VERSION ""

NS_ :

BS_:

BU_:

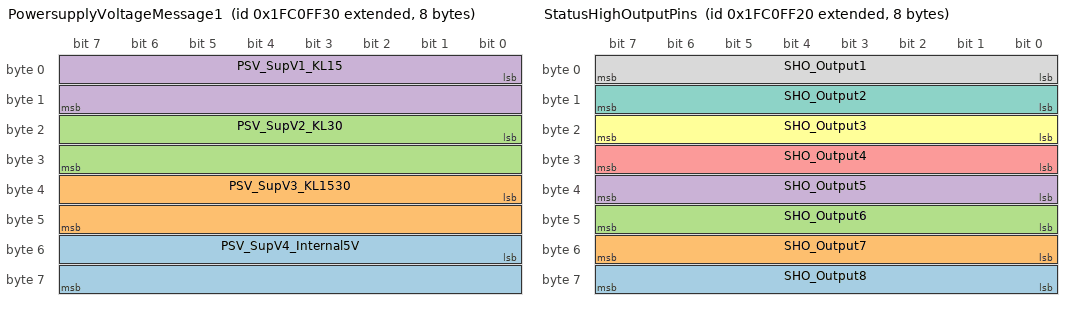
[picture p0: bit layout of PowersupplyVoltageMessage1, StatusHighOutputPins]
BO_ 2680225584 PowersupplyVoltageMessage1: 8 Vector__XXX
 SG_ PSV_SupV4_Internal5V : 48|16@1+ (0.01,0) [0|642.55] "V" Vector__XXX
 SG_ PSV_SupV3_KL1530 : 32|16@1+ (0.01,0) [0|642.55] "V" Vector__XXX
 SG_ PSV_SupV2_KL30 : 16|16@1+ (0.01,0) [0|642.55] "V" Vector__XXX
 SG_ PSV_SupV1_KL15 : 0|16@1+ (0.01,0) [0|642.55] "V" Vector__XXX

BO_ 2680225576 StatusLowOutputPins: 8 Vector__XXX
 SG_ SLO_Output2 : 8|8@1+ (1,0) [0|0] "" Vector__XXX
 SG_ SLO_Output1 : 0|8@1+ (1,0) [0|0] "" Vector__XXX

BO_ 2680225568 StatusHighOutputPins: 8 Vector__XXX
 SG_ SHO_Output8 : 56|8@1+ (1,0) [0|0] "" Vector__XXX
 SG_ SHO_Output7 : 48|8@1+ (1,0) [0|0] "" Vector__XXX
 SG_ SHO_Output6 : 40|8@1+ (1,0) [0|0] "" Vector__XXX
 SG_ SHO_Output5 : 32|8@1+ (1,0) [0|0] "" Vector__XXX
 SG_ SHO_Output4 : 24|8@1+ (1,0) [0|0] "" Vector__XXX
 SG_ SHO_Output3 : 16|8@1+ (1,0) [0|0] "" Vector__XXX
 SG_ SHO_Output2 : 8|8@1+ (1,0) [0|0] "" Vector__XXX
 SG_ SHO_Output1 : 0|8@1+ (1,0) [0|0] "" Vector__XXX

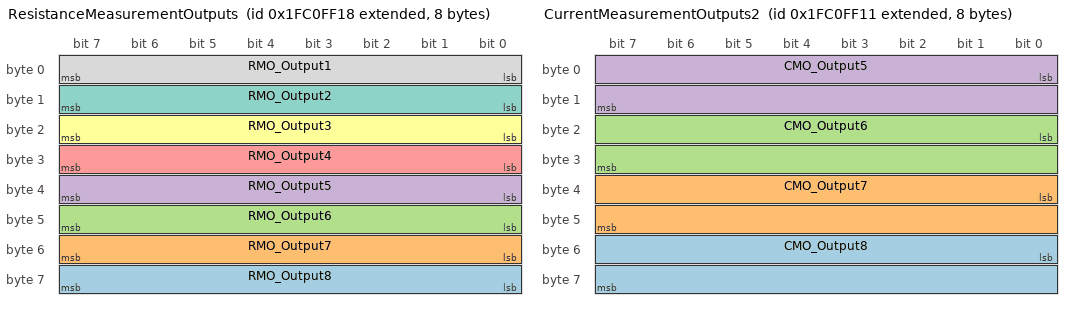
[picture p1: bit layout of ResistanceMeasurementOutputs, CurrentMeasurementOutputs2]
BO_ 2680225560 ResistanceMeasurementOutputs: 8 Vector__XXX
 SG_ RMO_Output8 : 56|8@1+ (0.25,0) [0|60] "Ohm" Vector__XXX
 SG_ RMO_Output7 : 48|8@1+ (0.25,0) [0|60] "Ohm" Vector__XXX
 SG_ RMO_Output6 : 40|8@1+ (0.25,0) [0|60] "Ohm" Vector__XXX
 SG_ RMO_Output5 : 32|8@1+ (0.25,0) [0|60] "Ohm" Vector__XXX
 SG_ RMO_Output4 : 24|8@1+ (0.25,0) [0|60] "Ohm" Vector__XXX
 SG_ RMO_Output3 : 16|8@1+ (0.25,0) [0|60] "Ohm" Vector__XXX
 SG_ RMO_Output2 : 8|8@1+ (0.25,0) [0|60] "Ohm" Vector__XXX
 SG_ RMO_Output1 : 0|8@1+ (0.25,0) [0|60] "Ohm" Vector__XXX

BO_ 2680225553 CurrentMeasurementOutputs2: 8 Vector__XXX
 SG_ CMO_Output8 : 48|16@1+ (0.001,0) [0|64255] "A" Vector__XXX
 SG_ CMO_Output7 : 32|16@1+ (0.001,0) [0|64255] "A" Vector__XXX
 SG_ CMO_Output6 : 16|16@1+ (0.001,0) [0|64255] "A" Vector__XXX
 SG_ CMO_Output5 : 0|16@1+ (0.001,0) [0|64255] "A" Vector__XXX

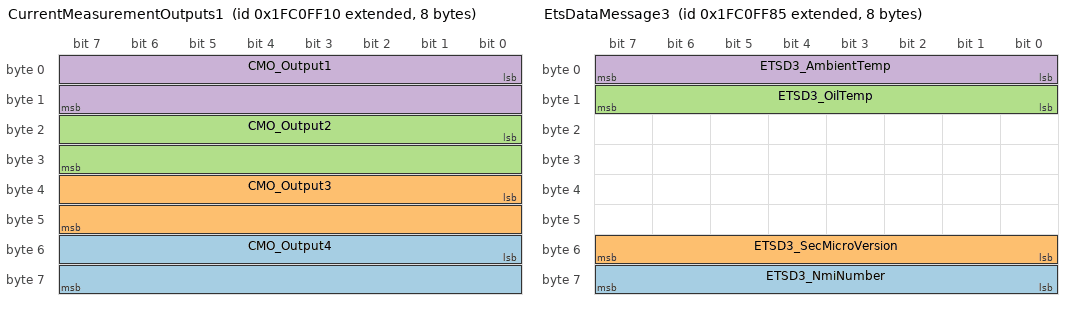
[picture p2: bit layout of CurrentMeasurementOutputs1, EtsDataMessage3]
BO_ 2680225552 CurrentMeasurementOutputs1: 8 Vector__XXX
 SG_ CMO_Output4 : 48|16@1+ (0.001,0) [0|64255] "A" Vector__XXX
 SG_ CMO_Output3 : 32|16@1+ (0.001,0) [0|64255] "A" Vector__XXX
 SG_ CMO_Output2 : 16|16@1+ (0.001,0) [0|64255] "A" Vector__XXX
 SG_ CMO_Output1 : 0|16@1+ (0.001,0) [0|64255] "A" Vector__XXX

BO_ 2680225669 EtsDataMessage3: 8 Vector__XXX
 SG_ ETSD3_NmiNumber : 56|8@1+ (1,0) [0|0] "" Vector__XXX
 SG_ ETSD3_SecMicroVersion : 48|8@1+ (1,0) [0|0] "" Vector__XXX
 SG_ ETSD3_OilTemp : 8|8@1+ (1,-40) [-40|210] "grd" Vector__XXX
 SG_ ETSD3_AmbientTemp : 0|8@1+ (1,-40) [-40|210] "grd" Vector__XXX

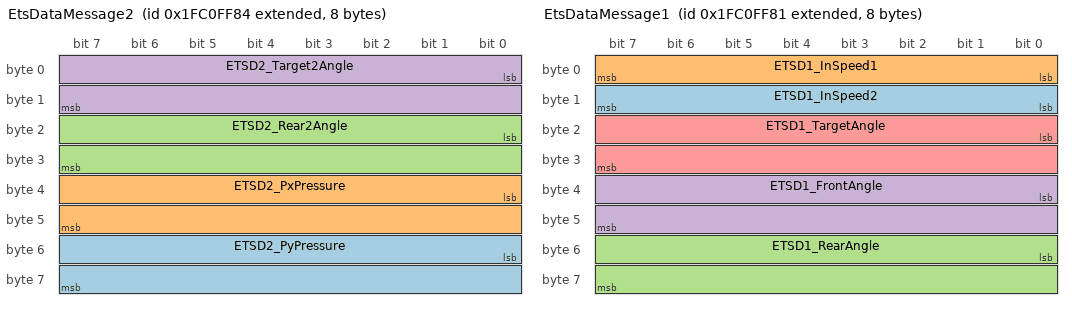
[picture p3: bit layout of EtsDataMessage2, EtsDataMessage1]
BO_ 2680225668 EtsDataMessage2: 8 Vector__XXX
 SG_ ETSD2_PyPressure : 48|16@1+ (0.02,0) [0|0] "Bar" Vector__XXX
 SG_ ETSD2_PxPressure : 32|16@1+ (0.02,0) [0|0] "Bar" Vector__XXX
 SG_ ETSD2_Rear2Angle : 16|16@1+ (0.00390625,-125) [-125|125] "grd" Vector__XXX
 SG_ ETSD2_Target2Angle : 0|16@1+ (0.00390625,-125) [-125|125] "grd" Vector__XXX

BO_ 2680225665 EtsDataMessage1: 8 Vector__XXX
 SG_ ETSD1_InSpeed2 : 8|8@1+ (1,0) [0|250] "km/h" Vector__XXX
 SG_ ETSD1_InSpeed1 : 0|8@1+ (1,0) [0|250] "km/h" Vector__XXX
 SG_ ETSD1_RearAngle : 48|16@1+ (0.00390625,-125) [-125|125] "Grd" Vector__XXX
 SG_ ETSD1_FrontAngle : 32|16@1+ (0.00390625,-125) [-125|125] "Grd" Vector__XXX
 SG_ ETSD1_TargetAngle : 16|16@1+ (0.00390625,-125) [-125|125] "Grd" Vector__XXX

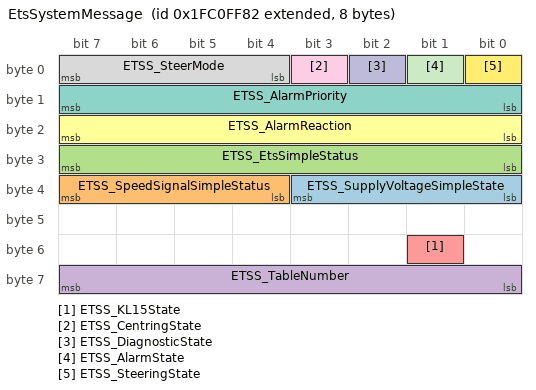
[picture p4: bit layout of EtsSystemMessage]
BO_ 2680225666 EtsSystemMessage: 8 Vector__XXX
 SG_ ETSS_SupplyVoltageSimpleState : 32|4@1+ (1,0) [0|0] "" Vector__XXX
 SG_ ETSS_SpeedSignalSimpleStatus : 36|4@1+ (1,0) [0|0] "" Vector__XXX
 SG_ ETSS_EtsSimpleStatus : 24|8@1+ (1,0) [0|0] "" Vector__XXX
 SG_ ETSS_TableNumber : 56|8@1+ (1,0) [0|255] "" Vector__XXX
 SG_ ETSS_KL15State : 49|1@1+ (1,0) [0|0] "" Vector__XXX
 SG_ ETSS_AlarmReaction : 16|8@1+ (1,0) [0|0] "" Vector__XXX
 SG_ ETSS_AlarmPriority : 8|8@1+ (1,0) [0|0] "" Vector__XXX
 SG_ ETSS_SteerMode : 4|4@1+ (1,0) [0|0] "" Vector__XXX
 SG_ ETSS_CentringState : 3|1@1+ (1,0) [0|0] "" Vector__XXX
 SG_ ETSS_DiagnosticState : 2|1@1+ (1,0) [0|0] "" Vector__XXX
 SG_ ETSS_AlarmState : 1|1@1+ (1,0) [0|0] "" Vector__XXX
 SG_ ETSS_SteeringState : 0|1@1+ (1,0) [0|0] "" Vector__XXX

VAL_ 2680225584 PSV_SupV4_Internal5V 65535 "Signal not available" 64510 "Not Defined" 64509 "Not Defined" 64508 "Not Defined" 64507 "Not Defined" 64506 "Not Defined" 64505 "Not Defined" 64504 "Not Defined" 64503 "Not Defined" 64502 "Not Defined" 64501 "Not Defined" 64500 "Not Defined" 64499 "Not Defined" 64498 "Not Defined" 64497 "Not Defined" 64496 "Not Defined" 64495 "Not Defined" 64494 "Not Defined" 64493 "Not Defined" 64492 "Not Defined" 64491 "Not Defined" 64490 "Not Defined" 64489 "Not Defined" 64488 "Not Defined" 64487 "Not Defined" 64486 "Not Defined" 64485 "Not Defined" 64484 "Not Defined" 64483 "Not Defined" 64482 "Not Defined" 64481 "Not Defined" 64480 "Not Defined" 64479 "Not Defined" 64478 "Not Defined" 64477 "Not Defined" 64476 "Not Defined" 64475 "Not Defined" 64474 "Not Defined" 64473 "Not Defined" 64472 "Not Defined" 64471 "Not Defined" 64470 "Not Defined" 64469 "Not Defined" 64468 "Not Defined" 64467 "Not Defined" 64466 "Not Defined" 64465 "Not Defined" 64464 "Not Defined" 64463 "Not Defined" 64462 "Not Defined" 64461 "Not Defined" 64460 "Not Defined" 64459 "Not Defined" 64458 "Not Defined" 64457 "Not Defined" 64456 "Not Defined" 64455 "Not Defined" 64454 "Not Defined" 64453 "Not Defined" 64452 "Not Defined" 64451 "Not Defined" 64450 "Not Defined" 64449 "Not Defined" 64448 "Not Defined" 64447 "Not Defined" 64446 "Not Defined" 64445 "Not Defined" 64444 "Not Defined" 64443 "Not Defined" 64442 "Not Defined" 64441 "Not Defined" 64440 "Not Defined" 64439 "Not Defined" 64438 "Not Defined" 64437 "Not Defined" 64436 "Not Defined" 64435 "Not Defined" 64434 "Not Defined" 64433 "Not Defined" 64432 "Not Defined" 64431 "Not Defined" 64430 "Not Defined" 64429 "Not Defined" 64428 "Not Defined" 64427 "Not Defined" 64426 "Not Defined" 64425 "Not Defined" 64424 "Not Defined" 64423 "Not Defined" 64422 "Not Defined" 64421 "Not Defined" 64420 "Not Defined" 64419 "Not Defined" 64418 "Not Defined" 64417 "Not Defined" 64416 "Not Defined" 64415 "Not Defined" 64414 "Not Defined" 64413 "Not Defined" 64412 "Not Defined" 64411 "Not Defined" 64410 "Not Defined" 64409 "Not Defined" 64408 "Not Defined" 64407 "Not Defined" 64406 "Not Defined" 64405 "Not Defined" 64404 "Not Defined" 64403 "Not Defined" 64402 "Not Defined" 64401 "Not Defined" 64400 "Not Defined" 64399 "Not Defined" 64398 "Not Defined" 64397 "Not Defined" 64396 "Not Defined" 64395 "Not Defined" 64394 "Not Defined" 64393 "Not Defined" 64392 "Not Defined" 64391 "Not Defined" 64390 "Not Defined" 64389 "Not Defined" 64388 "Not Defined" 64387 "Not Defined" 64386 "Not Defined" 64385 "Not Defined" 64384 "Not Defined" 64383 "Not Defined" 64382 "Not Defined" 64381 "Not Defined" 64380 "Not Defined" 64379 "Not Defined" 64378 "Not Defined" 64377 "Not Defined" 64376 "Not Defined" 64375 "Not Defined" 64374 "Not Defined" 64373 "Not Defined" 64372 "Not Defined" 64371 "Not Defined" 64370 "Not Defined" 64369 "Not Defined" 64368 "Not Defined" 64367 "Not Defined" 64366 "Not Defined" 64365 "Not Defined" 64364 "Not Defined" 64363 "Not Defined" 64362 "Not Defined" 64361 "Not Defined" 64360 "Not Defined" 64359 "Not Defined" 64358 "Not Defined" 64357 "Not Defined" 64356 "Not Defined" 64355 "Not Defined" 64354 "Not Defined" 64353 "Not Defined" 64352 "Not Defined" 64351 "Not Defined" 64350 "Not Defined" 64349 "Not Defined" 64348 "Not Defined" 64347 "Not Defined" 64346 "Not Defined" 64345 "Not Defined" 64344 "Not Defined" 64343 "Not Defined" 64342 "Not Defined" 64341 "Not Defined" 64340 "Not Defined" 64339 "Not Defined" 64338 "Not Defined" 64337 "Not Defined" 64336 "Not Defined" 64335 "Not Defined" 64334 "Not Defined" 64333 "Not Defined" 64332 "Not Defined" 64331 "Not Defined" 64330 "Not Defined" 64329 "Not Defined" 64328 "Not Defined" 64327 "Not Defined" 64326 "Not Defined" 64325 "Not Defined" 64324 "Not Defined" 64323 "Not Defined" 64322 "Not Defined" 64321 "Not Defined" 64320 "Not Defined" 64319 "Not Defined" 64318 "Not Defined" 64317 "Not Defined" 64316 "Not Defined" 64315 "Not Defined" 64314 "Not Defined" 64313 "Not Defined" 64312 "Not Defined" 64311 "Not Defined" 64310 "Not Defined" 64309 "Not Defined" 64308 "Not Defined" 64307 "Not Defined" 64306 "Not Defined" 64305 "Not Defined" 64304 "Not Defined" 64303 "Not Defined" 64302 "Not Defined" 64301 "Not Defined" 64300 "Not Defined" 64299 "Not Defined" 64298 "Not Defined" 64297 "Not Defined" 64296 "Not Defined" 64295 "Not Defined" 64294 "Not Defined" 64293 "Not Defined" 64292 "Not Defined" 64291 "Not Defined" 64290 "Not Defined" 64289 "Not Defined" 64288 "Not Defined" 64287 "Not Defined" 64286 "Not Defined" 64285 "Not Defined" 64284 "Not Defined" 64283 "Not Defined" 64282 "Not Defined" 64281 "Not Defined" 64280 "Not Defined" 64279 "Not Defined" 64278 "Not Defined" 64277 "Not Defined" 64276 "Not Defined" 64275 "Not Defined" 64274 "Not Defined" 64273 "Not Defined" 64272 "Not Defined" 64271 "Not Defined" 64270 "Not Defined" 64269 "Not Defined" 64268 "Not Defined" 64267 "Not Defined" 64266 "Not Defined" 64265 "Not Defined" 64264 "Not Defined" 64263 "Not Defined" 64262 "Not Defined" 64261 "Not Defined" 64260 "Not Defined" 64259 "Not Defined" 64258 "Not Defined" 64257 "Not Defined" 64256 "Not Defined" ;
VAL_ 2680225584 PSV_SupV3_KL1530 65535 "Signal not available" 64510 "Not Defined" 64509 "Not Defined" 64508 "Not Defined" 64507 "Not Defined" 64506 "Not Defined" 64505 "Not Defined" 64504 "Not Defined" 64503 "Not Defined" 64502 "Not Defined" 64501 "Not Defined" 64500 "Not Defined" 64499 "Not Defined" 64498 "Not Defined" 64497 "Not Defined" 64496 "Not Defined" 64495 "Not Defined" 64494 "Not Defined" 64493 "Not Defined" 64492 "Not Defined" 64491 "Not Defined" 64490 "Not Defined" 64489 "Not Defined" 64488 "Not Defined" 64487 "Not Defined" 64486 "Not Defined" 64485 "Not Defined" 64484 "Not Defined" 64483 "Not Defined" 64482 "Not Defined" 64481 "Not Defined" 64480 "Not Defined" 64479 "Not Defined" 64478 "Not Defined" 64477 "Not Defined" 64476 "Not Defined" 64475 "Not Defined" 64474 "Not Defined" 64473 "Not Defined" 64472 "Not Defined" 64471 "Not Defined" 64470 "Not Defined" 64469 "Not Defined" 64468 "Not Defined" 64467 "Not Defined" 64466 "Not Defined" 64465 "Not Defined" 64464 "Not Defined" 64463 "Not Defined" 64462 "Not Defined" 64461 "Not Defined" 64460 "Not Defined" 64459 "Not Defined" 64458 "Not Defined" 64457 "Not Defined" 64456 "Not Defined" 64455 "Not Defined" 64454 "Not Defined" 64453 "Not Defined" 64452 "Not Defined" 64451 "Not Defined" 64450 "Not Defined" 64449 "Not Defined" 64448 "Not Defined" 64447 "Not Defined" 64446 "Not Defined" 64445 "Not Defined" 64444 "Not Defined" 64443 "Not Defined" 64442 "Not Defined" 64441 "Not Defined" 64440 "Not Defined" 64439 "Not Defined" 64438 "Not Defined" 64437 "Not Defined" 64436 "Not Defined" 64435 "Not Defined" 64434 "Not Defined" 64433 "Not Defined" 64432 "Not Defined" 64431 "Not Defined" 64430 "Not Defined" 64429 "Not Defined" 64428 "Not Defined" 64427 "Not Defined" 64426 "Not Defined" 64425 "Not Defined" 64424 "Not Defined" 64423 "Not Defined" 64422 "Not Defined" 64421 "Not Defined" 64420 "Not Defined" 64419 "Not Defined" 64418 "Not Defined" 64417 "Not Defined" 64416 "Not Defined" 64415 "Not Defined" 64414 "Not Defined" 64413 "Not Defined" 64412 "Not Defined" 64411 "Not Defined" 64410 "Not Defined" 64409 "Not Defined" 64408 "Not Defined" 64407 "Not Defined" 64406 "Not Defined" 64405 "Not Defined" 64404 "Not Defined" 64403 "Not Defined" 64402 "Not Defined" 64401 "Not Defined" 64400 "Not Defined" 64399 "Not Defined" 64398 "Not Defined" 64397 "Not Defined" 64396 "Not Defined" 64395 "Not Defined" 64394 "Not Defined" 64393 "Not Defined" 64392 "Not Defined" 64391 "Not Defined" 64390 "Not Defined" 64389 "Not Defined" 64388 "Not Defined" 64387 "Not Defined" 64386 "Not Defined" 64385 "Not Defined" 64384 "Not Defined" 64383 "Not Defined" 64382 "Not Defined" 64381 "Not Defined" 64380 "Not Defined" 64379 "Not Defined" 64378 "Not Defined" 64377 "Not Defined" 64376 "Not Defined" 64375 "Not Defined" 64374 "Not Defined" 64373 "Not Defined" 64372 "Not Defined" 64371 "Not Defined" 64370 "Not Defined" 64369 "Not Defined" 64368 "Not Defined" 64367 "Not Defined" 64366 "Not Defined" 64365 "Not Defined" 64364 "Not Defined" 64363 "Not Defined" 64362 "Not Defined" 64361 "Not Defined" 64360 "Not Defined" 64359 "Not Defined" 64358 "Not Defined" 64357 "Not Defined" 64356 "Not Defined" 64355 "Not Defined" 64354 "Not Defined" 64353 "Not Defined" 64352 "Not Defined" 64351 "Not Defined" 64350 "Not Defined" 64349 "Not Defined" 64348 "Not Defined" 64347 "Not Defined" 64346 "Not Defined" 64345 "Not Defined" 64344 "Not Defined" 64343 "Not Defined" 64342 "Not Defined" 64341 "Not Defined" 64340 "Not Defined" 64339 "Not Defined" 64338 "Not Defined" 64337 "Not Defined" 64336 "Not Defined" 64335 "Not Defined" 64334 "Not Defined" 64333 "Not Defined" 64332 "Not Defined" 64331 "Not Defined" 64330 "Not Defined" 64329 "Not Defined" 64328 "Not Defined" 64327 "Not Defined" 64326 "Not Defined" 64325 "Not Defined" 64324 "Not Defined" 64323 "Not Defined" 64322 "Not Defined" 64321 "Not Defined" 64320 "Not Defined" 64319 "Not Defined" 64318 "Not Defined" 64317 "Not Defined" 64316 "Not Defined" 64315 "Not Defined" 64314 "Not Defined" 64313 "Not Defined" 64312 "Not Defined" 64311 "Not Defined" 64310 "Not Defined" 64309 "Not Defined" 64308 "Not Defined" 64307 "Not Defined" 64306 "Not Defined" 64305 "Not Defined" 64304 "Not Defined" 64303 "Not Defined" 64302 "Not Defined" 64301 "Not Defined" 64300 "Not Defined" 64299 "Not Defined" 64298 "Not Defined" 64297 "Not Defined" 64296 "Not Defined" 64295 "Not Defined" 64294 "Not Defined" 64293 "Not Defined" 64292 "Not Defined" 64291 "Not Defined" 64290 "Not Defined" 64289 "Not Defined" 64288 "Not Defined" 64287 "Not Defined" 64286 "Not Defined" 64285 "Not Defined" 64284 "Not Defined" 64283 "Not Defined" 64282 "Not Defined" 64281 "Not Defined" 64280 "Not Defined" 64279 "Not Defined" 64278 "Not Defined" 64277 "Not Defined" 64276 "Not Defined" 64275 "Not Defined" 64274 "Not Defined" 64273 "Not Defined" 64272 "Not Defined" 64271 "Not Defined" 64270 "Not Defined" 64269 "Not Defined" 64268 "Not Defined" 64267 "Not Defined" 64266 "Not Defined" 64265 "Not Defined" 64264 "Not Defined" 64263 "Not Defined" 64262 "Not Defined" 64261 "Not Defined" 64260 "Not Defined" 64259 "Not Defined" 64258 "Not Defined" 64257 "Not Defined" 64256 "Not Defined" ;
VAL_ 2680225584 PSV_SupV2_KL30 65535 "Signal not available" 64510 "Not Defined" 64509 "Not Defined" 64508 "Not Defined" 64507 "Not Defined" 64506 "Not Defined" 64505 "Not Defined" 64504 "Not Defined" 64503 "Not Defined" 64502 "Not Defined" 64501 "Not Defined" 64500 "Not Defined" 64499 "Not Defined" 64498 "Not Defined" 64497 "Not Defined" 64496 "Not Defined" 64495 "Not Defined" 64494 "Not Defined" 64493 "Not Defined" 64492 "Not Defined" 64491 "Not Defined" 64490 "Not Defined" 64489 "Not Defined" 64488 "Not Defined" 64487 "Not Defined" 64486 "Not Defined" 64485 "Not Defined" 64484 "Not Defined" 64483 "Not Defined" 64482 "Not Defined" 64481 "Not Defined" 64480 "Not Defined" 64479 "Not Defined" 64478 "Not Defined" 64477 "Not Defined" 64476 "Not Defined" 64475 "Not Defined" 64474 "Not Defined" 64473 "Not Defined" 64472 "Not Defined" 64471 "Not Defined" 64470 "Not Defined" 64469 "Not Defined" 64468 "Not Defined" 64467 "Not Defined" 64466 "Not Defined" 64465 "Not Defined" 64464 "Not Defined" 64463 "Not Defined" 64462 "Not Defined" 64461 "Not Defined" 64460 "Not Defined" 64459 "Not Defined" 64458 "Not Defined" 64457 "Not Defined" 64456 "Not Defined" 64455 "Not Defined" 64454 "Not Defined" 64453 "Not Defined" 64452 "Not Defined" 64451 "Not Defined" 64450 "Not Defined" 64449 "Not Defined" 64448 "Not Defined" 64447 "Not Defined" 64446 "Not Defined" 64445 "Not Defined" 64444 "Not Defined" 64443 "Not Defined" 64442 "Not Defined" 64441 "Not Defined" 64440 "Not Defined" 64439 "Not Defined" 64438 "Not Defined" 64437 "Not Defined" 64436 "Not Defined" 64435 "Not Defined" 64434 "Not Defined" 64433 "Not Defined" 64432 "Not Defined" 64431 "Not Defined" 64430 "Not Defined" 64429 "Not Defined" 64428 "Not Defined" 64427 "Not Defined" 64426 "Not Defined" 64425 "Not Defined" 64424 "Not Defined" 64423 "Not Defined" 64422 "Not Defined" 64421 "Not Defined" 64420 "Not Defined" 64419 "Not Defined" 64418 "Not Defined" 64417 "Not Defined" 64416 "Not Defined" 64415 "Not Defined" 64414 "Not Defined" 64413 "Not Defined" 64412 "Not Defined" 64411 "Not Defined" 64410 "Not Defined" 64409 "Not Defined" 64408 "Not Defined" 64407 "Not Defined" 64406 "Not Defined" 64405 "Not Defined" 64404 "Not Defined" 64403 "Not Defined" 64402 "Not Defined" 64401 "Not Defined" 64400 "Not Defined" 64399 "Not Defined" 64398 "Not Defined" 64397 "Not Defined" 64396 "Not Defined" 64395 "Not Defined" 64394 "Not Defined" 64393 "Not Defined" 64392 "Not Defined" 64391 "Not Defined" 64390 "Not Defined" 64389 "Not Defined" 64388 "Not Defined" 64387 "Not Defined" 64386 "Not Defined" 64385 "Not Defined" 64384 "Not Defined" 64383 "Not Defined" 64382 "Not Defined" 64381 "Not Defined" 64380 "Not Defined" 64379 "Not Defined" 64378 "Not Defined" 64377 "Not Defined" 64376 "Not Defined" 64375 "Not Defined" 64374 "Not Defined" 64373 "Not Defined" 64372 "Not Defined" 64371 "Not Defined" 64370 "Not Defined" 64369 "Not Defined" 64368 "Not Defined" 64367 "Not Defined" 64366 "Not Defined" 64365 "Not Defined" 64364 "Not Defined" 64363 "Not Defined" 64362 "Not Defined" 64361 "Not Defined" 64360 "Not Defined" 64359 "Not Defined" 64358 "Not Defined" 64357 "Not Defined" 64356 "Not Defined" 64355 "Not Defined" 64354 "Not Defined" 64353 "Not Defined" 64352 "Not Defined" 64351 "Not Defined" 64350 "Not Defined" 64349 "Not Defined" 64348 "Not Defined" 64347 "Not Defined" 64346 "Not Defined" 64345 "Not Defined" 64344 "Not Defined" 64343 "Not Defined" 64342 "Not Defined" 64341 "Not Defined" 64340 "Not Defined" 64339 "Not Defined" 64338 "Not Defined" 64337 "Not Defined" 64336 "Not Defined" 64335 "Not Defined" 64334 "Not Defined" 64333 "Not Defined" 64332 "Not Defined" 64331 "Not Defined" 64330 "Not Defined" 64329 "Not Defined" 64328 "Not Defined" 64327 "Not Defined" 64326 "Not Defined" 64325 "Not Defined" 64324 "Not Defined" 64323 "Not Defined" 64322 "Not Defined" 64321 "Not Defined" 64320 "Not Defined" 64319 "Not Defined" 64318 "Not Defined" 64317 "Not Defined" 64316 "Not Defined" 64315 "Not Defined" 64314 "Not Defined" 64313 "Not Defined" 64312 "Not Defined" 64311 "Not Defined" 64310 "Not Defined" 64309 "Not Defined" 64308 "Not Defined" 64307 "Not Defined" 64306 "Not Defined" 64305 "Not Defined" 64304 "Not Defined" 64303 "Not Defined" 64302 "Not Defined" 64301 "Not Defined" 64300 "Not Defined" 64299 "Not Defined" 64298 "Not Defined" 64297 "Not Defined" 64296 "Not Defined" 64295 "Not Defined" 64294 "Not Defined" 64293 "Not Defined" 64292 "Not Defined" 64291 "Not Defined" 64290 "Not Defined" 64289 "Not Defined" 64288 "Not Defined" 64287 "Not Defined" 64286 "Not Defined" 64285 "Not Defined" 64284 "Not Defined" 64283 "Not Defined" 64282 "Not Defined" 64281 "Not Defined" 64280 "Not Defined" 64279 "Not Defined" 64278 "Not Defined" 64277 "Not Defined" 64276 "Not Defined" 64275 "Not Defined" 64274 "Not Defined" 64273 "Not Defined" 64272 "Not Defined" 64271 "Not Defined" 64270 "Not Defined" 64269 "Not Defined" 64268 "Not Defined" 64267 "Not Defined" 64266 "Not Defined" 64265 "Not Defined" 64264 "Not Defined" 64263 "Not Defined" 64262 "Not Defined" 64261 "Not Defined" 64260 "Not Defined" 64259 "Not Defined" 64258 "Not Defined" 64257 "Not Defined" 64256 "Not Defined" ;
VAL_ 2680225584 PSV_SupV1_KL15 65535 "Signal not available" 64510 "Not Defined" 64509 "Not Defined" 64508 "Not Defined" 64507 "Not Defined" 64506 "Not Defined" 64505 "Not Defined" 64504 "Not Defined" 64503 "Not Defined" 64502 "Not Defined" 64501 "Not Defined" 64500 "Not Defined" 64499 "Not Defined" 64498 "Not Defined" 64497 "Not Defined" 64496 "Not Defined" 64495 "Not Defined" 64494 "Not Defined" 64493 "Not Defined" 64492 "Not Defined" 64491 "Not Defined" 64490 "Not Defined" 64489 "Not Defined" 64488 "Not Defined" 64487 "Not Defined" 64486 "Not Defined" 64485 "Not Defined" 64484 "Not Defined" 64483 "Not Defined" 64482 "Not Defined" 64481 "Not Defined" 64480 "Not Defined" 64479 "Not Defined" 64478 "Not Defined" 64477 "Not Defined" 64476 "Not Defined" 64475 "Not Defined" 64474 "Not Defined" 64473 "Not Defined" 64472 "Not Defined" 64471 "Not Defined" 64470 "Not Defined" 64469 "Not Defined" 64468 "Not Defined" 64467 "Not Defined" 64466 "Not Defined" 64465 "Not Defined" 64464 "Not Defined" 64463 "Not Defined" 64462 "Not Defined" 64461 "Not Defined" 64460 "Not Defined" 64459 "Not Defined" 64458 "Not Defined" 64457 "Not Defined" 64456 "Not Defined" 64455 "Not Defined" 64454 "Not Defined" 64453 "Not Defined" 64452 "Not Defined" 64451 "Not Defined" 64450 "Not Defined" 64449 "Not Defined" 64448 "Not Defined" 64447 "Not Defined" 64446 "Not Defined" 64445 "Not Defined" 64444 "Not Defined" 64443 "Not Defined" 64442 "Not Defined" 64441 "Not Defined" 64440 "Not Defined" 64439 "Not Defined" 64438 "Not Defined" 64437 "Not Defined" 64436 "Not Defined" 64435 "Not Defined" 64434 "Not Defined" 64433 "Not Defined" 64432 "Not Defined" 64431 "Not Defined" 64430 "Not Defined" 64429 "Not Defined" 64428 "Not Defined" 64427 "Not Defined" 64426 "Not Defined" 64425 "Not Defined" 64424 "Not Defined" 64423 "Not Defined" 64422 "Not Defined" 64421 "Not Defined" 64420 "Not Defined" 64419 "Not Defined" 64418 "Not Defined" 64417 "Not Defined" 64416 "Not Defined" 64415 "Not Defined" 64414 "Not Defined" 64413 "Not Defined" 64412 "Not Defined" 64411 "Not Defined" 64410 "Not Defined" 64409 "Not Defined" 64408 "Not Defined" 64407 "Not Defined" 64406 "Not Defined" 64405 "Not Defined" 64404 "Not Defined" 64403 "Not Defined" 64402 "Not Defined" 64401 "Not Defined" 64400 "Not Defined" 64399 "Not Defined" 64398 "Not Defined" 64397 "Not Defined" 64396 "Not Defined" 64395 "Not Defined" 64394 "Not Defined" 64393 "Not Defined" 64392 "Not Defined" 64391 "Not Defined" 64390 "Not Defined" 64389 "Not Defined" 64388 "Not Defined" 64387 "Not Defined" 64386 "Not Defined" 64385 "Not Defined" 64384 "Not Defined" 64383 "Not Defined" 64382 "Not Defined" 64381 "Not Defined" 64380 "Not Defined" 64379 "Not Defined" 64378 "Not Defined" 64377 "Not Defined" 64376 "Not Defined" 64375 "Not Defined" 64374 "Not Defined" 64373 "Not Defined" 64372 "Not Defined" 64371 "Not Defined" 64370 "Not Defined" 64369 "Not Defined" 64368 "Not Defined" 64367 "Not Defined" 64366 "Not Defined" 64365 "Not Defined" 64364 "Not Defined" 64363 "Not Defined" 64362 "Not Defined" 64361 "Not Defined" 64360 "Not Defined" 64359 "Not Defined" 64358 "Not Defined" 64357 "Not Defined" 64356 "Not Defined" 64355 "Not Defined" 64354 "Not Defined" 64353 "Not Defined" 64352 "Not Defined" 64351 "Not Defined" 64350 "Not Defined" 64349 "Not Defined" 64348 "Not Defined" 64347 "Not Defined" 64346 "Not Defined" 64345 "Not Defined" 64344 "Not Defined" 64343 "Not Defined" 64342 "Not Defined" 64341 "Not Defined" 64340 "Not Defined" 64339 "Not Defined" 64338 "Not Defined" 64337 "Not Defined" 64336 "Not Defined" 64335 "Not Defined" 64334 "Not Defined" 64333 "Not Defined" 64332 "Not Defined" 64331 "Not Defined" 64330 "Not Defined" 64329 "Not Defined" 64328 "Not Defined" 64327 "Not Defined" 64326 "Not Defined" 64325 "Not Defined" 64324 "Not Defined" 64323 "Not Defined" 64322 "Not Defined" 64321 "Not Defined" 64320 "Not Defined" 64319 "Not Defined" 64318 "Not Defined" 64317 "Not Defined" 64316 "Not Defined" 64315 "Not Defined" 64314 "Not Defined" 64313 "Not Defined" 64312 "Not Defined" 64311 "Not Defined" 64310 "Not Defined" 64309 "Not Defined" 64308 "Not Defined" 64307 "Not Defined" 64306 "Not Defined" 64305 "Not Defined" 64304 "Not Defined" 64303 "Not Defined" 64302 "Not Defined" 64301 "Not Defined" 64300 "Not Defined" 64299 "Not Defined" 64298 "Not Defined" 64297 "Not Defined" 64296 "Not Defined" 64295 "Not Defined" 64294 "Not Defined" 64293 "Not Defined" 64292 "Not Defined" 64291 "Not Defined" 64290 "Not Defined" 64289 "Not Defined" 64288 "Not Defined" 64287 "Not Defined" 64286 "Not Defined" 64285 "Not Defined" 64284 "Not Defined" 64283 "Not Defined" 64282 "Not Defined" 64281 "Not Defined" 64280 "Not Defined" 64279 "Not Defined" 64278 "Not Defined" 64277 "Not Defined" 64276 "Not Defined" 64275 "Not Defined" 64274 "Not Defined" 64273 "Not Defined" 64272 "Not Defined" 64271 "Not Defined" 64270 "Not Defined" 64269 "Not Defined" 64268 "Not Defined" 64267 "Not Defined" 64266 "Not Defined" 64265 "Not Defined" 64264 "Not Defined" 64263 "Not Defined" 64262 "Not Defined" 64261 "Not Defined" 64260 "Not Defined" 64259 "Not Defined" 64258 "Not Defined" 64257 "Not Defined" 64256 "Not Defined" ;
VAL_ 2680225576 SLO_Output2 255 "Low Output status not available" 254 "Low Output status not available" 253 "Low Output status not available" 252 "Low Output status not available" 251 "Low Output status not available" 250 "Low Output status not available" 249 "Low Output status not available" 248 "Low Output status not available" 247 "Low Output status not available" 246 "Low Output status not available" 245 "Low Output status not available" 244 "Low Output status not available" 243 "Low Output status not available" 242 "Low Output status not available" 241 "Low Output status not available" 240 "Low Output status not available" 239 "Not Defined" 238 "Not Defined" 237 "Not Defined" 236 "Not Defined" 235 "Not Defined" 234 "Not Defined" 233 "Not Defined" 232 "Not Defined" 231 "Not Defined" 230 "Not Defined" 229 "Not Defined" 228 "Not Defined" 227 "Not Defined" 226 "Not Defined" 225 "Not Defined" 224 "Not Defined" 223 "Not Defined" 222 "Not Defined" 221 "Not Defined" 220 "Not Defined" 219 "Not Defined" 218 "Not Defined" 217 "Not Defined" 216 "Not Defined" 215 "Not Defined" 214 "Not Defined" 213 "Not Defined" 212 "Not Defined" 211 "Not Defined" 210 "Not Defined" 209 "Not Defined" 208 "Not Defined" 207 "Not Defined" 206 "Not Defined" 205 "Not Defined" 204 "Not Defined" 203 "Not Defined" 202 "Not Defined" 201 "Not Defined" 200 "Not Defined" 199 "Not Defined" 198 "Not Defined" 197 "Not Defined" 196 "Not Defined" 195 "Not Defined" 194 "Not Defined" 193 "Not Defined" 192 "Not Defined" 191 "Not Defined" 190 "Not Defined" 189 "Not Defined" 188 "Not Defined" 187 "Not Defined" 186 "Not Defined" 185 "Not Defined" 184 "Not Defined" 183 "Not Defined" 182 "Not Defined" 181 "Not Defined" 180 "Not Defined" 179 "Not Defined" 178 "Not Defined" 177 "Not Defined" 176 "Not Defined" 175 "Not Defined" 174 "Not Defined" 173 "Not Defined" 172 "Not Defined" 171 "Not Defined" 170 "Not Defined" 169 "Not Defined" 168 "Not Defined" 167 "Not Defined" 166 "Not Defined" 165 "Not Defined" 164 "Not Defined" 163 "Not Defined" 162 "Not Defined" 161 "Not Defined" 160 "Not Defined" 159 "Not Defined" 158 "Not Defined" 157 "Not Defined" 156 "Not Defined" 155 "Not Defined" 154 "Not Defined" 153 "Not Defined" 152 "Not Defined" 151 "Not Defined" 150 "Not Defined" 149 "Not Defined" 148 "Not Defined" 147 "Not Defined" 146 "Not Defined" 145 "Not Defined" 144 "Not Defined" 143 "Not Defined" 142 "Not Defined" 141 "Not Defined" 140 "Not Defined" 139 "Not Defined" 138 "Not Defined" 137 "Not Defined" 136 "Not Defined" 135 "Not Defined" 134 "Not Defined" 133 "Not Defined" 132 "Not Defined" 131 "Not Defined" 130 "Not Defined" 129 "Not Defined" 128 "Not Defined" 127 "Not Defined" 126 "Not Defined" 125 "Not Defined" 124 "Not Defined" 123 "Not Defined" 122 "Not Defined" 121 "Not Defined" 120 "Not Defined" 119 "Not Defined" 118 "Not Defined" 117 "Not Defined" 116 "Not Defined" 115 "Not Defined" 114 "Not Defined" 113 "Not Defined" 112 "Not Defined" 111 "Not Defined" 110 "Not Defined" 109 "Not Defined" 108 "Not Defined" 107 "Not Defined" 106 "Not Defined" 105 "Not Defined" 104 "Not Defined" 103 "Not Defined" 102 "Not Defined" 101 "Not Defined" 100 "Not Defined" 99 "Not Defined" 98 "Not Defined" 97 "Not Defined" 96 "Not Defined" 95 "Not Defined" 94 "Not Defined" 93 "Not Defined" 92 "Not Defined" 91 "Not Defined" 90 "Not Defined" 89 "Not Defined" 88 "Not Defined" 87 "Not Defined" 86 "Not Defined" 85 "Not Defined" 84 "Not Defined" 83 "Not Defined" 82 "Not Defined" 81 "Not Defined" 80 "Not Defined" 79 "Not Defined" 78 "Not Defined" 77 "Not Defined" 76 "Not Defined" 75 "Not Defined" 74 "Not Defined" 73 "Not Defined" 72 "Not Defined" 71 "Not Defined" 70 "Not Defined" 69 "Not Defined" 68 "Not Defined" 67 "Not Defined" 66 "Not Defined" 65 "Not Defined" 64 "Not Defined" 63 "Not Defined" 62 "Not Defined" 61 "Not Defined" 60 "Not Defined" 59 "Not Defined" 58 "Not Defined" 57 "Not Defined" 56 "Not Defined" 55 "Not Defined" 54 "Not Defined" 53 "Not Defined" 52 "Not Defined" 51 "Not Defined" 50 "Not Defined" 49 "Not Defined" 48 "Not Defined" 47 "Not Defined" 46 "Not Defined" 45 "Not Defined" 44 "Not Defined" 43 "Not Defined" 42 "Not Defined" 41 "Not Defined" 40 "Not Defined" 39 "Not Defined" 38 "Not Defined" 37 "Not Defined" 36 "Not Defined" 35 "Not Defined" 34 "Not Defined" 33 "Low Output On Status Not Define" 32 "Low Output Off Status Not Defin" 31 "Not Defined" 30 "Not Defined" 29 "Not Defined" 28 "Not Defined" 27 "Not Defined" 26 "Not Defined" 25 "Not Defined" 24 "Not Defined" 23 "Not Defined" 22 "Not Defined" 21 "Not Defined" 20 "Not Defined" 19 "Not Defined" 18 "Not Defined" 17 "Low Output In Status Nok" 16 "Low Output Off Status Nok" 15 "Low Output Not Available" 14 "Not Defined" 13 "Not Defined" 12 "Not Defined" 11 "Not Defined" 10 "Not Defined" 9 "Not Defined" 8 "Not Defined" 7 "Not Defined" 6 "Not Defined" 5 "Not Defined" 4 "Not Defined" 3 "Not Defined" 2 "Not Defined" 1 "Low Output ON Status Ok" 0 "Low Output Off Status Ok" ;
VAL_ 2680225576 SLO_Output1 255 "Low Output status not available" 254 "Low Output status not available" 253 "Low Output status not available" 252 "Low Output status not available" 251 "Low Output status not available" 250 "Low Output status not available" 249 "Low Output status not available" 248 "Low Output status not available" 247 "Low Output status not available" 246 "Low Output status not available" 245 "Low Output status not available" 244 "Low Output status not available" 243 "Low Output status not available" 242 "Low Output status not available" 241 "Low Output status not available" 240 "Low Output status not available" 239 "Not Defined" 238 "Not Defined" 237 "Not Defined" 236 "Not Defined" 235 "Not Defined" 234 "Not Defined" 233 "Not Defined" 232 "Not Defined" 231 "Not Defined" 230 "Not Defined" 229 "Not Defined" 228 "Not Defined" 227 "Not Defined" 226 "Not Defined" 225 "Not Defined" 224 "Not Defined" 223 "Not Defined" 222 "Not Defined" 221 "Not Defined" 220 "Not Defined" 219 "Not Defined" 218 "Not Defined" 217 "Not Defined" 216 "Not Defined" 215 "Not Defined" 214 "Not Defined" 213 "Not Defined" 212 "Not Defined" 211 "Not Defined" 210 "Not Defined" 209 "Not Defined" 208 "Not Defined" 207 "Not Defined" 206 "Not Defined" 205 "Not Defined" 204 "Not Defined" 203 "Not Defined" 202 "Not Defined" 201 "Not Defined" 200 "Not Defined" 199 "Not Defined" 198 "Not Defined" 197 "Not Defined" 196 "Not Defined" 195 "Not Defined" 194 "Not Defined" 193 "Not Defined" 192 "Not Defined" 191 "Not Defined" 190 "Not Defined" 189 "Not Defined" 188 "Not Defined" 187 "Not Defined" 186 "Not Defined" 185 "Not Defined" 184 "Not Defined" 183 "Not Defined" 182 "Not Defined" 181 "Not Defined" 180 "Not Defined" 179 "Not Defined" 178 "Not Defined" 177 "Not Defined" 176 "Not Defined" 175 "Not Defined" 174 "Not Defined" 173 "Not Defined" 172 "Not Defined" 171 "Not Defined" 170 "Not Defined" 169 "Not Defined" 168 "Not Defined" 167 "Not Defined" 166 "Not Defined" 165 "Not Defined" 164 "Not Defined" 163 "Not Defined" 162 "Not Defined" 161 "Not Defined" 160 "Not Defined" 159 "Not Defined" 158 "Not Defined" 157 "Not Defined" 156 "Not Defined" 155 "Not Defined" 154 "Not Defined" 153 "Not Defined" 152 "Not Defined" 151 "Not Defined" 150 "Not Defined" 149 "Not Defined" 148 "Not Defined" 147 "Not Defined" 146 "Not Defined" 145 "Not Defined" 144 "Not Defined" 143 "Not Defined" 142 "Not Defined" 141 "Not Defined" 140 "Not Defined" 139 "Not Defined" 138 "Not Defined" 137 "Not Defined" 136 "Not Defined" 135 "Not Defined" 134 "Not Defined" 133 "Not Defined" 132 "Not Defined" 131 "Not Defined" 130 "Not Defined" 129 "Not Defined" 128 "Not Defined" 127 "Not Defined" 126 "Not Defined" 125 "Not Defined" 124 "Not Defined" 123 "Not Defined" 122 "Not Defined" 121 "Not Defined" 120 "Not Defined" 119 "Not Defined" 118 "Not Defined" 117 "Not Defined" 116 "Not Defined" 115 "Not Defined" 114 "Not Defined" 113 "Not Defined" 112 "Not Defined" 111 "Not Defined" 110 "Not Defined" 109 "Not Defined" 108 "Not Defined" 107 "Not Defined" 106 "Not Defined" 105 "Not Defined" 104 "Not Defined" 103 "Not Defined" 102 "Not Defined" 101 "Not Defined" 100 "Not Defined" 99 "Not Defined" 98 "Not Defined" 97 "Not Defined" 96 "Not Defined" 95 "Not Defined" 94 "Not Defined" 93 "Not Defined" 92 "Not Defined" 91 "Not Defined" 90 "Not Defined" 89 "Not Defined" 88 "Not Defined" 87 "Not Defined" 86 "Not Defined" 85 "Not Defined" 84 "Not Defined" 83 "Not Defined" 82 "Not Defined" 81 "Not Defined" 80 "Not Defined" 79 "Not Defined" 78 "Not Defined" 77 "Not Defined" 76 "Not Defined" 75 "Not Defined" 74 "Not Defined" 73 "Not Defined" 72 "Not Defined" 71 "Not Defined" 70 "Not Defined" 69 "Not Defined" 68 "Not Defined" 67 "Not Defined" 66 "Not Defined" 65 "Not Defined" 64 "Not Defined" 63 "Not Defined" 62 "Not Defined" 61 "Not Defined" 60 "Not Defined" 59 "Not Defined" 58 "Not Defined" 57 "Not Defined" 56 "Not Defined" 55 "Not Defined" 54 "Not Defined" 53 "Not Defined" 52 "Not Defined" 51 "Not Defined" 50 "Not Defined" 49 "Not Defined" 48 "Not Defined" 47 "Not Defined" 46 "Not Defined" 45 "Not Defined" 44 "Not Defined" 43 "Not Defined" 42 "Not Defined" 41 "Not Defined" 40 "Not Defined" 39 "Not Defined" 38 "Not Defined" 37 "Not Defined" 36 "Not Defined" 35 "Not Defined" 34 "Not Defined" 33 "Low Output On Status Not Define" 32 "Low Output Off Status Not Define" 31 "Not Defined" 30 "Not Defined" 29 "Not Defined" 28 "Not Defined" 27 "Not Defined" 26 "Not Defined" 25 "Not Defined" 24 "Not Defined" 23 "Not Defined" 22 "Not Defined" 21 "Not Defined" 20 "Not Defined" 19 "Not Defined" 18 "Not Defined" 17 "Low Output In Status Nok" 16 "Low Output Off Status Nok" 15 "Low Output Not Available" 14 "Not Defined" 13 "Not Defined" 12 "Not Defined" 11 "Not Defined" 10 "Not Defined" 9 "Not Defined" 8 "Not Defined" 7 "Not Defined" 6 "Not Defined" 5 "Not Defined" 4 "Not Defined" 3 "Not Defined" 2 "Not Defined" 1 "Low Output ON Status Ok" 0 "Low Output Off Status Ok" ;
VAL_ 2680225568 SHO_Output8 255 "High Output status not available" 254 "High Output status not available" 253 "High Output status not available" 252 "High Output status not available" 251 "High Output status not available" 250 "High Output status not available" 249 "High Output status not available" 248 "High Output status not available" 247 "High Output status not available" 246 "High Output status not available" 245 "High Output status not available" 244 "High Output status not available" 243 "High Output status not available" 242 "High Output status not available" 241 "High Output status not available" 240 "High Output status not available" 239 "Not Defined" 238 "Not Defined" 237 "Not Defined" 236 "Not Defined" 235 "Not Defined" 234 "Not Defined" 233 "Not Defined" 232 "Not Defined" 231 "Not Defined" 230 "Not Defined" 229 "Not Defined" 228 "Not Defined" 227 "Not Defined" 226 "Not Defined" 225 "Not Defined" 224 "Not Defined" 223 "Not Defined" 222 "Not Defined" 221 "Not Defined" 220 "Not Defined" 219 "Not Defined" 218 "Not Defined" 217 "Not Defined" 216 "Not Defined" 215 "Not Defined" 214 "Not Defined" 213 "Not Defined" 212 "Not Defined" 211 "Not Defined" 210 "Not Defined" 209 "Not Defined" 208 "Not Defined" 207 "Not Defined" 206 "Not Defined" 205 "Not Defined" 204 "Not Defined" 203 "Not Defined" 202 "Not Defined" 201 "Not Defined" 200 "Not Defined" 199 "Not Defined" 198 "Not Defined" 197 "Not Defined" 196 "Not Defined" 195 "Not Defined" 194 "Not Defined" 193 "Not Defined" 192 "Not Defined" 191 "Not Defined" 190 "Not Defined" 189 "Not Defined" 188 "Not Defined" 187 "Not Defined" 186 "Not Defined" 185 "Not Defined" 184 "Not Defined" 183 "Not Defined" 182 "Not Defined" 181 "Not Defined" 180 "Not Defined" 179 "Not Defined" 178 "Not Defined" 177 "Not Defined" 176 "Not Defined" 175 "Not Defined" 174 "Not Defined" 173 "Not Defined" 172 "Not Defined" 171 "Not Defined" 170 "Not Defined" 169 "Not Defined" 168 "Not Defined" 167 "Not Defined" 166 "Not Defined" 165 "Not Defined" 164 "Not Defined" 163 "Not Defined" 162 "Not Defined" 161 "Not Defined" 160 "Not Defined" 159 "Not Defined" 158 "Not Defined" 157 "Not Defined" 156 "Not Defined" 155 "Not Defined" 154 "Not Defined" 153 "Not Defined" 152 "Not Defined" 151 "Not Defined" 150 "Not Defined" 149 "Not Defined" 148 "Not Defined" 147 "Not Defined" 146 "Not Defined" 145 "Not Defined" 144 "Not Defined" 143 "Not Defined" 142 "Not Defined" 141 "Not Defined" 140 "Not Defined" 139 "Not Defined" 138 "Not Defined" 137 "Not Defined" 136 "Not Defined" 135 "Not Defined" 134 "Not Defined" 133 "Not Defined" 132 "Not Defined" 131 "Not Defined" 130 "Not Defined" 129 "Not Defined" 128 "Not Defined" 127 "Not Defined" 126 "Not Defined" 125 "Not Defined" 124 "Not Defined" 123 "Not Defined" 122 "Not Defined" 121 "Not Defined" 120 "Not Defined" 119 "Not Defined" 118 "Not Defined" 117 "Not Defined" 116 "Not Defined" 115 "Not Defined" 114 "Not Defined" 113 "Not Defined" 112 "Not Defined" 111 "Not Defined" 110 "Not Defined" 109 "Not Defined" 108 "Not Defined" 107 "Not Defined" 106 "Not Defined" 105 "Not Defined" 104 "Not Defined" 103 "Not Defined" 102 "Not Defined" 101 "Not Defined" 100 "Not Defined" 99 "Not Defined" 98 "Not Defined" 97 "Not Defined" 96 "Not Defined" 95 "Not Defined" 94 "Not Defined" 93 "Not Defined" 92 "Not Defined" 91 "Not Defined" 90 "Not Defined" 89 "Not Defined" 88 "Not Defined" 87 "Not Defined" 86 "Not Defined" 85 "Not Defined" 84 "Not Defined" 83 "Not Defined" 82 "Not Defined" 81 "Not Defined" 80 "Not Defined" 79 "Not Defined" 78 "Not Defined" 77 "Not Defined" 76 "Not Defined" 75 "Not Defined" 74 "Not Defined" 73 "Not Defined" 72 "Not Defined" 71 "Not Defined" 70 "Not Defined" 69 "Not Defined" 68 "Not Defined" 67 "Not Defined" 66 "Not Defined" 65 "Not Defined" 64 "Not Defined" 63 "Not Defined" 62 "Not Defined" 61 "Not Defined" 60 "Not Defined" 59 "Not Defined" 58 "Not Defined" 57 "Not Defined" 56 "Not Defined" 55 "Not Defined" 54 "Not Defined" 53 "Not Defined" 52 "Not Defined" 51 "Not Defined" 50 "Not Defined" 49 "Not Defined" 48 "Not Defined" 47 "Not Defined" 46 "Not Defined" 45 "Not Defined" 44 "Not Defined" 43 "Not Defined" 42 "Not Defined" 41 "Not Defined" 40 "Not Defined" 39 "Not Defined" 38 "Not Defined" 37 "Not Defined" 36 "Not Defined" 35 "Not Defined" 34 "Not Defined" 33 "High Output On Status Not Define" 32 "High Output Off Status Not Defin" 31 "Not Defined" 30 "Not Defined" 29 "Not Defined" 28 "Not Defined" 27 "Not Defined" 26 "Not Defined" 25 "Not Defined" 24 "Not Defined" 23 "Not Defined" 22 "Not Defined" 21 "Not Defined" 20 "Not Defined" 19 "Not Defined" 18 "Not Defined" 17 "High Output In Status Nok" 16 "High Output Off Status Nok" 15 "High Output Not Available" 14 "Not Defined" 13 "Not Defined" 12 "Not Defined" 11 "Not Defined" 10 "Not Defined" 9 "Not Defined" 8 "Not Defined" 7 "Not Defined" 6 "Not Defined" 5 "Not Defined" 4 "Not Defined" 3 "Not Defined" 2 "Not Defined" 1 "High Output ON Status Ok" 0 "High Output Off Status Ok" ;
VAL_ 2680225568 SHO_Output7 255 "High Output status not available" 254 "High Output status not available" 253 "High Output status not available" 252 "High Output status not available" 251 "High Output status not available" 250 "High Output status not available" 249 "High Output status not available" 248 "High Output status not available" 247 "High Output status not available" 246 "High Output status not available" 245 "High Output status not available" 244 "High Output status not available" 243 "High Output status not available" 242 "High Output status not available" 241 "High Output status not available" 240 "High Output status not available" 239 "Not Defined" 238 "Not Defined" 237 "Not Defined" 236 "Not Defined" 235 "Not Defined" 234 "Not Defined" 233 "Not Defined" 232 "Not Defined" 231 "Not Defined" 230 "Not Defined" 229 "Not Defined" 228 "Not Defined" 227 "Not Defined" 226 "Not Defined" 225 "Not Defined" 224 "Not Defined" 223 "Not Defined" 222 "Not Defined" 221 "Not Defined" 220 "Not Defined" 219 "Not Defined" 218 "Not Defined" 217 "Not Defined" 216 "Not Defined" 215 "Not Defined" 214 "Not Defined" 213 "Not Defined" 212 "Not Defined" 211 "Not Defined" 210 "Not Defined" 209 "Not Defined" 208 "Not Defined" 207 "Not Defined" 206 "Not Defined" 205 "Not Defined" 204 "Not Defined" 203 "Not Defined" 202 "Not Defined" 201 "Not Defined" 200 "Not Defined" 199 "Not Defined" 198 "Not Defined" 197 "Not Defined" 196 "Not Defined" 195 "Not Defined" 194 "Not Defined" 193 "Not Defined" 192 "Not Defined" 191 "Not Defined" 190 "Not Defined" 189 "Not Defined" 188 "Not Defined" 187 "Not Defined" 186 "Not Defined" 185 "Not Defined" 184 "Not Defined" 183 "Not Defined" 182 "Not Defined" 181 "Not Defined" 180 "Not Defined" 179 "Not Defined" 178 "Not Defined" 177 "Not Defined" 176 "Not Defined" 175 "Not Defined" 174 "Not Defined" 173 "Not Defined" 172 "Not Defined" 171 "Not Defined" 170 "Not Defined" 169 "Not Defined" 168 "Not Defined" 167 "Not Defined" 166 "Not Defined" 165 "Not Defined" 164 "Not Defined" 163 "Not Defined" 162 "Not Defined" 161 "Not Defined" 160 "Not Defined" 159 "Not Defined" 158 "Not Defined" 157 "Not Defined" 156 "Not Defined" 155 "Not Defined" 154 "Not Defined" 153 "Not Defined" 152 "Not Defined" 151 "Not Defined" 150 "Not Defined" 149 "Not Defined" 148 "Not Defined" 147 "Not Defined" 146 "Not Defined" 145 "Not Defined" 144 "Not Defined" 143 "Not Defined" 142 "Not Defined" 141 "Not Defined" 140 "Not Defined" 139 "Not Defined" 138 "Not Defined" 137 "Not Defined" 136 "Not Defined" 135 "Not Defined" 134 "Not Defined" 133 "Not Defined" 132 "Not Defined" 131 "Not Defined" 130 "Not Defined" 129 "Not Defined" 128 "Not Defined" 127 "Not Defined" 126 "Not Defined" 125 "Not Defined" 124 "Not Defined" 123 "Not Defined" 122 "Not Defined" 121 "Not Defined" 120 "Not Defined" 119 "Not Defined" 118 "Not Defined" 117 "Not Defined" 116 "Not Defined" 115 "Not Defined" 114 "Not Defined" 113 "Not Defined" 112 "Not Defined" 111 "Not Defined" 110 "Not Defined" 109 "Not Defined" 108 "Not Defined" 107 "Not Defined" 106 "Not Defined" 105 "Not Defined" 104 "Not Defined" 103 "Not Defined" 102 "Not Defined" 101 "Not Defined" 100 "Not Defined" 99 "Not Defined" 98 "Not Defined" 97 "Not Defined" 96 "Not Defined" 95 "Not Defined" 94 "Not Defined" 93 "Not Defined" 92 "Not Defined" 91 "Not Defined" 90 "Not Defined" 89 "Not Defined" 88 "Not Defined" 87 "Not Defined" 86 "Not Defined" 85 "Not Defined" 84 "Not Defined" 83 "Not Defined" 82 "Not Defined" 81 "Not Defined" 80 "Not Defined" 79 "Not Defined" 78 "Not Defined" 77 "Not Defined" 76 "Not Defined" 75 "Not Defined" 74 "Not Defined" 73 "Not Defined" 72 "Not Defined" 71 "Not Defined" 70 "Not Defined" 69 "Not Defined" 68 "Not Defined" 67 "Not Defined" 66 "Not Defined" 65 "Not Defined" 64 "Not Defined" 63 "Not Defined" 62 "Not Defined" 61 "Not Defined" 60 "Not Defined" 59 "Not Defined" 58 "Not Defined" 57 "Not Defined" 56 "Not Defined" 55 "Not Defined" 54 "Not Defined" 53 "Not Defined" 52 "Not Defined" 51 "Not Defined" 50 "Not Defined" 49 "Not Defined" 48 "Not Defined" 47 "Not Defined" 46 "Not Defined" 45 "Not Defined" 44 "Not Defined" 43 "Not Defined" 42 "Not Defined" 41 "Not Defined" 40 "Not Defined" 39 "Not Defined" 38 "Not Defined" 37 "Not Defined" 36 "Not Defined" 35 "Not Defined" 34 "Not Defined" 33 "High Output On Status Not Define" 32 "High Output Off Status Not Defin" 31 "Not Defined" 30 "Not Defined" 29 "Not Defined" 28 "Not Defined" 27 "Not Defined" 26 "Not Defined" 25 "Not Defined" 24 "Not Defined" 23 "Not Defined" 22 "Not Defined" 21 "Not Defined" 20 "Not Defined" 19 "Not Defined" 18 "Not Defined" 17 "High Output In Status Nok" 16 "High Output Off Status Nok" 15 "High Output Not Available" 14 "Not Defined" 13 "Not Defined" 12 "Not Defined" 11 "Not Defined" 10 "Not Defined" 9 "Not Defined" 8 "Not Defined" 7 "Not Defined" 6 "Not Defined" 5 "Not Defined" 4 "Not Defined" 3 "Not Defined" 2 "Not Defined" 1 "High Output ON Status Ok" 0 "High Output Off Status Ok" ;
VAL_ 2680225568 SHO_Output6 255 "High Output status not available" 254 "High Output status not available" 253 "High Output status not available" 252 "High Output status not available" 251 "High Output status not available" 250 "High Output status not available" 249 "High Output status not available" 248 "High Output status not available" 247 "High Output status not available" 246 "High Output status not available" 245 "High Output status not available" 244 "High Output status not available" 243 "High Output status not available" 242 "High Output status not available" 241 "High Output status not available" 240 "High Output status not available" 239 "Not Defined" 238 "Not Defined" 237 "Not Defined" 236 "Not Defined" 235 "Not Defined" 234 "Not Defined" 233 "Not Defined" 232 "Not Defined" 231 "Not Defined" 230 "Not Defined" 229 "Not Defined" 228 "Not Defined" 227 "Not Defined" 226 "Not Defined" 225 "Not Defined" 224 "Not Defined" 223 "Not Defined" 222 "Not Defined" 221 "Not Defined" 220 "Not Defined" 219 "Not Defined" 218 "Not Defined" 217 "Not Defined" 216 "Not Defined" 215 "Not Defined" 214 "Not Defined" 213 "Not Defined" 212 "Not Defined" 211 "Not Defined" 210 "Not Defined" 209 "Not Defined" 208 "Not Defined" 207 "Not Defined" 206 "Not Defined" 205 "Not Defined" 204 "Not Defined" 203 "Not Defined" 202 "Not Defined" 201 "Not Defined" 200 "Not Defined" 199 "Not Defined" 198 "Not Defined" 197 "Not Defined" 196 "Not Defined" 195 "Not Defined" 194 "Not Defined" 193 "Not Defined" 192 "Not Defined" 191 "Not Defined" 190 "Not Defined" 189 "Not Defined" 188 "Not Defined" 187 "Not Defined" 186 "Not Defined" 185 "Not Defined" 184 "Not Defined" 183 "Not Defined" 182 "Not Defined" 181 "Not Defined" 180 "Not Defined" 179 "Not Defined" 178 "Not Defined" 177 "Not Defined" 176 "Not Defined" 175 "Not Defined" 174 "Not Defined" 173 "Not Defined" 172 "Not Defined" 171 "Not Defined" 170 "Not Defined" 169 "Not Defined" 168 "Not Defined" 167 "Not Defined" 166 "Not Defined" 165 "Not Defined" 164 "Not Defined" 163 "Not Defined" 162 "Not Defined" 161 "Not Defined" 160 "Not Defined" 159 "Not Defined" 158 "Not Defined" 157 "Not Defined" 156 "Not Defined" 155 "Not Defined" 154 "Not Defined" 153 "Not Defined" 152 "Not Defined" 151 "Not Defined" 150 "Not Defined" 149 "Not Defined" 148 "Not Defined" 147 "Not Defined" 146 "Not Defined" 145 "Not Defined" 144 "Not Defined" 143 "Not Defined" 142 "Not Defined" 141 "Not Defined" 140 "Not Defined" 139 "Not Defined" 138 "Not Defined" 137 "Not Defined" 136 "Not Defined" 135 "Not Defined" 134 "Not Defined" 133 "Not Defined" 132 "Not Defined" 131 "Not Defined" 130 "Not Defined" 129 "Not Defined" 128 "Not Defined" 127 "Not Defined" 126 "Not Defined" 125 "Not Defined" 124 "Not Defined" 123 "Not Defined" 122 "Not Defined" 121 "Not Defined" 120 "Not Defined" 119 "Not Defined" 118 "Not Defined" 117 "Not Defined" 116 "Not Defined" 115 "Not Defined" 114 "Not Defined" 113 "Not Defined" 112 "Not Defined" 111 "Not Defined" 110 "Not Defined" 109 "Not Defined" 108 "Not Defined" 107 "Not Defined" 106 "Not Defined" 105 "Not Defined" 104 "Not Defined" 103 "Not Defined" 102 "Not Defined" 101 "Not Defined" 100 "Not Defined" 99 "Not Defined" 98 "Not Defined" 97 "Not Defined" 96 "Not Defined" 95 "Not Defined" 94 "Not Defined" 93 "Not Defined" 92 "Not Defined" 91 "Not Defined" 90 "Not Defined" 89 "Not Defined" 88 "Not Defined" 87 "Not Defined" 86 "Not Defined" 85 "Not Defined" 84 "Not Defined" 83 "Not Defined" 82 "Not Defined" 81 "Not Defined" 80 "Not Defined" 79 "Not Defined" 78 "Not Defined" 77 "Not Defined" 76 "Not Defined" 75 "Not Defined" 74 "Not Defined" 73 "Not Defined" 72 "Not Defined" 71 "Not Defined" 70 "Not Defined" 69 "Not Defined" 68 "Not Defined" 67 "Not Defined" 66 "Not Defined" 65 "Not Defined" 64 "Not Defined" 63 "Not Defined" 62 "Not Defined" 61 "Not Defined" 60 "Not Defined" 59 "Not Defined" 58 "Not Defined" 57 "Not Defined" 56 "Not Defined" 55 "Not Defined" 54 "Not Defined" 53 "Not Defined" 52 "Not Defined" 51 "Not Defined" 50 "Not Defined" 49 "Not Defined" 48 "Not Defined" 47 "Not Defined" 46 "Not Defined" 45 "Not Defined" 44 "Not Defined" 43 "Not Defined" 42 "Not Defined" 41 "Not Defined" 40 "Not Defined" 39 "Not Defined" 38 "Not Defined" 37 "Not Defined" 36 "Not Defined" 35 "Not Defined" 34 "Not Defined" 33 "High Output On Status Not Define" 32 "High Output Off Status Not Defin" 31 "Not Defined" 30 "Not Defined" 29 "Not Defined" 28 "Not Defined" 27 "Not Defined" 26 "Not Defined" 25 "Not Defined" 24 "Not Defined" 23 "Not Defined" 22 "Not Defined" 21 "Not Defined" 20 "Not Defined" 19 "Not Defined" 18 "Not Defined" 17 "High Output In Status Nok" 16 "High Output Off Status Nok" 15 "High Output Not Available" 14 "Not Defined" 13 "Not Defined" 12 "Not Defined" 11 "Not Defined" 10 "Not Defined" 9 "Not Defined" 8 "Not Defined" 7 "Not Defined" 6 "Not Defined" 5 "Not Defined" 4 "Not Defined" 3 "Not Defined" 2 "Not Defined" 1 "High Output ON Status Ok" 0 "High Output Off Status Ok" ;
VAL_ 2680225568 SHO_Output5 255 "High Output status not available" 254 "High Output status not available" 253 "High Output status not available" 252 "High Output status not available" 251 "High Output status not available" 250 "High Output status not available" 249 "High Output status not available" 248 "High Output status not available" 247 "High Output status not available" 246 "High Output status not available" 245 "High Output status not available" 244 "High Output status not available" 243 "High Output status not available" 242 "High Output status not available" 241 "High Output status not available" 240 "High Output status not available" 239 "Not Defined" 238 "Not Defined" 237 "Not Defined" 236 "Not Defined" 235 "Not Defined" 234 "Not Defined" 233 "Not Defined" 232 "Not Defined" 231 "Not Defined" 230 "Not Defined" 229 "Not Defined" 228 "Not Defined" 227 "Not Defined" 226 "Not Defined" 225 "Not Defined" 224 "Not Defined" 223 "Not Defined" 222 "Not Defined" 221 "Not Defined" 220 "Not Defined" 219 "Not Defined" 218 "Not Defined" 217 "Not Defined" 216 "Not Defined" 215 "Not Defined" 214 "Not Defined" 213 "Not Defined" 212 "Not Defined" 211 "Not Defined" 210 "Not Defined" 209 "Not Defined" 208 "Not Defined" 207 "Not Defined" 206 "Not Defined" 205 "Not Defined" 204 "Not Defined" 203 "Not Defined" 202 "Not Defined" 201 "Not Defined" 200 "Not Defined" 199 "Not Defined" 198 "Not Defined" 197 "Not Defined" 196 "Not Defined" 195 "Not Defined" 194 "Not Defined" 193 "Not Defined" 192 "Not Defined" 191 "Not Defined" 190 "Not Defined" 189 "Not Defined" 188 "Not Defined" 187 "Not Defined" 186 "Not Defined" 185 "Not Defined" 184 "Not Defined" 183 "Not Defined" 182 "Not Defined" 181 "Not Defined" 180 "Not Defined" 179 "Not Defined" 178 "Not Defined" 177 "Not Defined" 176 "Not Defined" 175 "Not Defined" 174 "Not Defined" 173 "Not Defined" 172 "Not Defined" 171 "Not Defined" 170 "Not Defined" 169 "Not Defined" 168 "Not Defined" 167 "Not Defined" 166 "Not Defined" 165 "Not Defined" 164 "Not Defined" 163 "Not Defined" 162 "Not Defined" 161 "Not Defined" 160 "Not Defined" 159 "Not Defined" 158 "Not Defined" 157 "Not Defined" 156 "Not Defined" 155 "Not Defined" 154 "Not Defined" 153 "Not Defined" 152 "Not Defined" 151 "Not Defined" 150 "Not Defined" 149 "Not Defined" 148 "Not Defined" 147 "Not Defined" 146 "Not Defined" 145 "Not Defined" 144 "Not Defined" 143 "Not Defined" 142 "Not Defined" 141 "Not Defined" 140 "Not Defined" 139 "Not Defined" 138 "Not Defined" 137 "Not Defined" 136 "Not Defined" 135 "Not Defined" 134 "Not Defined" 133 "Not Defined" 132 "Not Defined" 131 "Not Defined" 130 "Not Defined" 129 "Not Defined" 128 "Not Defined" 127 "Not Defined" 126 "Not Defined" 125 "Not Defined" 124 "Not Defined" 123 "Not Defined" 122 "Not Defined" 121 "Not Defined" 120 "Not Defined" 119 "Not Defined" 118 "Not Defined" 117 "Not Defined" 116 "Not Defined" 115 "Not Defined" 114 "Not Defined" 113 "Not Defined" 112 "Not Defined" 111 "Not Defined" 110 "Not Defined" 109 "Not Defined" 108 "Not Defined" 107 "Not Defined" 106 "Not Defined" 105 "Not Defined" 104 "Not Defined" 103 "Not Defined" 102 "Not Defined" 101 "Not Defined" 100 "Not Defined" 99 "Not Defined" 98 "Not Defined" 97 "Not Defined" 96 "Not Defined" 95 "Not Defined" 94 "Not Defined" 93 "Not Defined" 92 "Not Defined" 91 "Not Defined" 90 "Not Defined" 89 "Not Defined" 88 "Not Defined" 87 "Not Defined" 86 "Not Defined" 85 "Not Defined" 84 "Not Defined" 83 "Not Defined" 82 "Not Defined" 81 "Not Defined" 80 "Not Defined" 79 "Not Defined" 78 "Not Defined" 77 "Not Defined" 76 "Not Defined" 75 "Not Defined" 74 "Not Defined" 73 "Not Defined" 72 "Not Defined" 71 "Not Defined" 70 "Not Defined" 69 "Not Defined" 68 "Not Defined" 67 "Not Defined" 66 "Not Defined" 65 "Not Defined" 64 "Not Defined" 63 "Not Defined" 62 "Not Defined" 61 "Not Defined" 60 "Not Defined" 59 "Not Defined" 58 "Not Defined" 57 "Not Defined" 56 "Not Defined" 55 "Not Defined" 54 "Not Defined" 53 "Not Defined" 52 "Not Defined" 51 "Not Defined" 50 "Not Defined" 49 "Not Defined" 48 "Not Defined" 47 "Not Defined" 46 "Not Defined" 45 "Not Defined" 44 "Not Defined" 43 "Not Defined" 42 "Not Defined" 41 "Not Defined" 40 "Not Defined" 39 "Not Defined" 38 "Not Defined" 37 "Not Defined" 36 "Not Defined" 35 "Not Defined" 34 "Not Defined" 33 "High Output On Status Not Define" 32 "High Output Off Status Not Defin" 31 "Not Defined" 30 "Not Defined" 29 "Not Defined" 28 "Not Defined" 27 "Not Defined" 26 "Not Defined" 25 "Not Defined" 24 "Not Defined" 23 "Not Defined" 22 "Not Defined" 21 "Not Defined" 20 "Not Defined" 19 "Not Defined" 18 "Not Defined" 17 "High Output In Status Nok" 16 "High Output Off Status Nok" 15 "High Output Not Available" 14 "Not Defined" 13 "Not Defined" 12 "Not Defined" 11 "Not Defined" 10 "Not Defined" 9 "Not Defined" 8 "Not Defined" 7 "Not Defined" 6 "Not Defined" 5 "Not Defined" 4 "Not Defined" 3 "Not Defined" 2 "Not Defined" 1 "High Output ON Status Ok" 0 "High Output Off Status Ok" ;
VAL_ 2680225568 SHO_Output4 255 "High Output status not available" 254 "High Output status not available" 253 "High Output status not available" 252 "High Output status not available" 251 "High Output status not available" 250 "High Output status not available" 249 "High Output status not available" 248 "High Output status not available" 247 "High Output status not available" 246 "High Output status not available" 245 "High Output status not available" 244 "High Output status not available" 243 "High Output status not available" 242 "High Output status not available" 241 "High Output status not available" 240 "High Output status not available" 239 "Not Defined" 238 "Not Defined" 237 "Not Defined" 236 "Not Defined" 235 "Not Defined" 234 "Not Defined" 233 "Not Defined" 232 "Not Defined" 231 "Not Defined" 230 "Not Defined" 229 "Not Defined" 228 "Not Defined" 227 "Not Defined" 226 "Not Defined" 225 "Not Defined" 224 "Not Defined" 223 "Not Defined" 222 "Not Defined" 221 "Not Defined" 220 "Not Defined" 219 "Not Defined" 218 "Not Defined" 217 "Not Defined" 216 "Not Defined" 215 "Not Defined" 214 "Not Defined" 213 "Not Defined" 212 "Not Defined" 211 "Not Defined" 210 "Not Defined" 209 "Not Defined" 208 "Not Defined" 207 "Not Defined" 206 "Not Defined" 205 "Not Defined" 204 "Not Defined" 203 "Not Defined" 202 "Not Defined" 201 "Not Defined" 200 "Not Defined" 199 "Not Defined" 198 "Not Defined" 197 "Not Defined" 196 "Not Defined" 195 "Not Defined" 194 "Not Defined" 193 "Not Defined" 192 "Not Defined" 191 "Not Defined" 190 "Not Defined" 189 "Not Defined" 188 "Not Defined" 187 "Not Defined" 186 "Not Defined" 185 "Not Defined" 184 "Not Defined" 183 "Not Defined" 182 "Not Defined" 181 "Not Defined" 180 "Not Defined" 179 "Not Defined" 178 "Not Defined" 177 "Not Defined" 176 "Not Defined" 175 "Not Defined" 174 "Not Defined" 173 "Not Defined" 172 "Not Defined" 171 "Not Defined" 170 "Not Defined" 169 "Not Defined" 168 "Not Defined" 167 "Not Defined" 166 "Not Defined" 165 "Not Defined" 164 "Not Defined" 163 "Not Defined" 162 "Not Defined" 161 "Not Defined" 160 "Not Defined" 159 "Not Defined" 158 "Not Defined" 157 "Not Defined" 156 "Not Defined" 155 "Not Defined" 154 "Not Defined" 153 "Not Defined" 152 "Not Defined" 151 "Not Defined" 150 "Not Defined" 149 "Not Defined" 148 "Not Defined" 147 "Not Defined" 146 "Not Defined" 145 "Not Defined" 144 "Not Defined" 143 "Not Defined" 142 "Not Defined" 141 "Not Defined" 140 "Not Defined" 139 "Not Defined" 138 "Not Defined" 137 "Not Defined" 136 "Not Defined" 135 "Not Defined" 134 "Not Defined" 133 "Not Defined" 132 "Not Defined" 131 "Not Defined" 130 "Not Defined" 129 "Not Defined" 128 "Not Defined" 127 "Not Defined" 126 "Not Defined" 125 "Not Defined" 124 "Not Defined" 123 "Not Defined" 122 "Not Defined" 121 "Not Defined" 120 "Not Defined" 119 "Not Defined" 118 "Not Defined" 117 "Not Defined" 116 "Not Defined" 115 "Not Defined" 114 "Not Defined" 113 "Not Defined" 112 "Not Defined" 111 "Not Defined" 110 "Not Defined" 109 "Not Defined" 108 "Not Defined" 107 "Not Defined" 106 "Not Defined" 105 "Not Defined" 104 "Not Defined" 103 "Not Defined" 102 "Not Defined" 101 "Not Defined" 100 "Not Defined" 99 "Not Defined" 98 "Not Defined" 97 "Not Defined" 96 "Not Defined" 95 "Not Defined" 94 "Not Defined" 93 "Not Defined" 92 "Not Defined" 91 "Not Defined" 90 "Not Defined" 89 "Not Defined" 88 "Not Defined" 87 "Not Defined" 86 "Not Defined" 85 "Not Defined" 84 "Not Defined" 83 "Not Defined" 82 "Not Defined" 81 "Not Defined" 80 "Not Defined" 79 "Not Defined" 78 "Not Defined" 77 "Not Defined" 76 "Not Defined" 75 "Not Defined" 74 "Not Defined" 73 "Not Defined" 72 "Not Defined" 71 "Not Defined" 70 "Not Defined" 69 "Not Defined" 68 "Not Defined" 67 "Not Defined" 66 "Not Defined" 65 "Not Defined" 64 "Not Defined" 63 "Not Defined" 62 "Not Defined" 61 "Not Defined" 60 "Not Defined" 59 "Not Defined" 58 "Not Defined" 57 "Not Defined" 56 "Not Defined" 55 "Not Defined" 54 "Not Defined" 53 "Not Defined" 52 "Not Defined" 51 "Not Defined" 50 "Not Defined" 49 "Not Defined" 48 "Not Defined" 47 "Not Defined" 46 "Not Defined" 45 "Not Defined" 44 "Not Defined" 43 "Not Defined" 42 "Not Defined" 41 "Not Defined" 40 "Not Defined" 39 "Not Defined" 38 "Not Defined" 37 "Not Defined" 36 "Not Defined" 35 "Not Defined" 34 "Not Defined" 33 "High Output On Status Not Define" 32 "High Output Off Status Not Defin" 31 "Not Defined" 30 "Not Defined" 29 "Not Defined" 28 "Not Defined" 27 "Not Defined" 26 "Not Defined" 25 "Not Defined" 24 "Not Defined" 23 "Not Defined" 22 "Not Defined" 21 "Not Defined" 20 "Not Defined" 19 "Not Defined" 18 "Not Defined" 17 "High Output In Status Nok" 16 "High Output Off Status Nok" 15 "High Output Not Available" 14 "Not Defined" 13 "Not Defined" 12 "Not Defined" 11 "Not Defined" 10 "Not Defined" 9 "Not Defined" 8 "Not Defined" 7 "Not Defined" 6 "Not Defined" 5 "Not Defined" 4 "Not Defined" 3 "Not Defined" 2 "Not Defined" 1 "High Output ON Status Ok" 0 "High Output Off Status Ok" ;
VAL_ 2680225568 SHO_Output3 255 "High Output status not available" 254 "High Output status not available" 253 "High Output status not available" 252 "High Output status not available" 251 "High Output status not available" 250 "High Output status not available" 249 "High Output status not available" 248 "High Output status not available" 247 "High Output status not available" 246 "High Output status not available" 245 "High Output status not available" 244 "High Output status not available" 243 "High Output status not available" 242 "High Output status not available" 241 "High Output status not available" 240 "High Output status not available" 239 "Not Defined" 238 "Not Defined" 237 "Not Defined" 236 "Not Defined" 235 "Not Defined" 234 "Not Defined" 233 "Not Defined" 232 "Not Defined" 231 "Not Defined" 230 "Not Defined" 229 "Not Defined" 228 "Not Defined" 227 "Not Defined" 226 "Not Defined" 225 "Not Defined" 224 "Not Defined" 223 "Not Defined" 222 "Not Defined" 221 "Not Defined" 220 "Not Defined" 219 "Not Defined" 218 "Not Defined" 217 "Not Defined" 216 "Not Defined" 215 "Not Defined" 214 "Not Defined" 213 "Not Defined" 212 "Not Defined" 211 "Not Defined" 210 "Not Defined" 209 "Not Defined" 208 "Not Defined" 207 "Not Defined" 206 "Not Defined" 205 "Not Defined" 204 "Not Defined" 203 "Not Defined" 202 "Not Defined" 201 "Not Defined" 200 "Not Defined" 199 "Not Defined" 198 "Not Defined" 197 "Not Defined" 196 "Not Defined" 195 "Not Defined" 194 "Not Defined" 193 "Not Defined" 192 "Not Defined" 191 "Not Defined" 190 "Not Defined" 189 "Not Defined" 188 "Not Defined" 187 "Not Defined" 186 "Not Defined" 185 "Not Defined" 184 "Not Defined" 183 "Not Defined" 182 "Not Defined" 181 "Not Defined" 180 "Not Defined" 179 "Not Defined" 178 "Not Defined" 177 "Not Defined" 176 "Not Defined" 175 "Not Defined" 174 "Not Defined" 173 "Not Defined" 172 "Not Defined" 171 "Not Defined" 170 "Not Defined" 169 "Not Defined" 168 "Not Defined" 167 "Not Defined" 166 "Not Defined" 165 "Not Defined" 164 "Not Defined" 163 "Not Defined" 162 "Not Defined" 161 "Not Defined" 160 "Not Defined" 159 "Not Defined" 158 "Not Defined" 157 "Not Defined" 156 "Not Defined" 155 "Not Defined" 154 "Not Defined" 153 "Not Defined" 152 "Not Defined" 151 "Not Defined" 150 "Not Defined" 149 "Not Defined" 148 "Not Defined" 147 "Not Defined" 146 "Not Defined" 145 "Not Defined" 144 "Not Defined" 143 "Not Defined" 142 "Not Defined" 141 "Not Defined" 140 "Not Defined" 139 "Not Defined" 138 "Not Defined" 137 "Not Defined" 136 "Not Defined" 135 "Not Defined" 134 "Not Defined" 133 "Not Defined" 132 "Not Defined" 131 "Not Defined" 130 "Not Defined" 129 "Not Defined" 128 "Not Defined" 127 "Not Defined" 126 "Not Defined" 125 "Not Defined" 124 "Not Defined" 123 "Not Defined" 122 "Not Defined" 121 "Not Defined" 120 "Not Defined" 119 "Not Defined" 118 "Not Defined" 117 "Not Defined" 116 "Not Defined" 115 "Not Defined" 114 "Not Defined" 113 "Not Defined" 112 "Not Defined" 111 "Not Defined" 110 "Not Defined" 109 "Not Defined" 108 "Not Defined" 107 "Not Defined" 106 "Not Defined" 105 "Not Defined" 104 "Not Defined" 103 "Not Defined" 102 "Not Defined" 101 "Not Defined" 100 "Not Defined" 99 "Not Defined" 98 "Not Defined" 97 "Not Defined" 96 "Not Defined" 95 "Not Defined" 94 "Not Defined" 93 "Not Defined" 92 "Not Defined" 91 "Not Defined" 90 "Not Defined" 89 "Not Defined" 88 "Not Defined" 87 "Not Defined" 86 "Not Defined" 85 "Not Defined" 84 "Not Defined" 83 "Not Defined" 82 "Not Defined" 81 "Not Defined" 80 "Not Defined" 79 "Not Defined" 78 "Not Defined" 77 "Not Defined" 76 "Not Defined" 75 "Not Defined" 74 "Not Defined" 73 "Not Defined" 72 "Not Defined" 71 "Not Defined" 70 "Not Defined" 69 "Not Defined" 68 "Not Defined" 67 "Not Defined" 66 "Not Defined" 65 "Not Defined" 64 "Not Defined" 63 "Not Defined" 62 "Not Defined" 61 "Not Defined" 60 "Not Defined" 59 "Not Defined" 58 "Not Defined" 57 "Not Defined" 56 "Not Defined" 55 "Not Defined" 54 "Not Defined" 53 "Not Defined" 52 "Not Defined" 51 "Not Defined" 50 "Not Defined" 49 "Not Defined" 48 "Not Defined" 47 "Not Defined" 46 "Not Defined" 45 "Not Defined" 44 "Not Defined" 43 "Not Defined" 42 "Not Defined" 41 "Not Defined" 40 "Not Defined" 39 "Not Defined" 38 "Not Defined" 37 "Not Defined" 36 "Not Defined" 35 "Not Defined" 34 "Not Defined" 33 "High Output On Status Not Define" 32 "High Output Off Status Not Defin" 31 "Not Defined" 30 "Not Defined" 29 "Not Defined" 28 "Not Defined" 27 "Not Defined" 26 "Not Defined" 25 "Not Defined" 24 "Not Defined" 23 "Not Defined" 22 "Not Defined" 21 "Not Defined" 20 "Not Defined" 19 "Not Defined" 18 "Not Defined" 17 "High Output In Status Nok" 16 "High Output Off Status Nok" 15 "High Output Not Available" 14 "Not Defined" 13 "Not Defined" 12 "Not Defined" 11 "Not Defined" 10 "Not Defined" 9 "Not Defined" 8 "Not Defined" 7 "Not Defined" 6 "Not Defined" 5 "Not Defined" 4 "Not Defined" 3 "Not Defined" 2 "Not Defined" 1 "High Output ON Status Ok" 0 "High Output Off Status Ok" ;
VAL_ 2680225568 SHO_Output2 255 "High Output status not available" 254 "High Output status not available" 253 "High Output status not available" 252 "High Output status not available" 251 "High Output status not available" 250 "High Output status not available" 249 "High Output status not available" 248 "High Output status not available" 247 "High Output status not available" 246 "High Output status not available" 245 "High Output status not available" 244 "High Output status not available" 243 "High Output status not available" 242 "High Output status not available" 241 "High Output status not available" 240 "High Output status not available" 239 "Not Defined" 238 "Not Defined" 237 "Not Defined" 236 "Not Defined" 235 "Not Defined" 234 "Not Defined" 233 "Not Defined" 232 "Not Defined" 231 "Not Defined" 230 "Not Defined" 229 "Not Defined" 228 "Not Defined" 227 "Not Defined" 226 "Not Defined" 225 "Not Defined" 224 "Not Defined" 223 "Not Defined" 222 "Not Defined" 221 "Not Defined" 220 "Not Defined" 219 "Not Defined" 218 "Not Defined" 217 "Not Defined" 216 "Not Defined" 215 "Not Defined" 214 "Not Defined" 213 "Not Defined" 212 "Not Defined" 211 "Not Defined" 210 "Not Defined" 209 "Not Defined" 208 "Not Defined" 207 "Not Defined" 206 "Not Defined" 205 "Not Defined" 204 "Not Defined" 203 "Not Defined" 202 "Not Defined" 201 "Not Defined" 200 "Not Defined" 199 "Not Defined" 198 "Not Defined" 197 "Not Defined" 196 "Not Defined" 195 "Not Defined" 194 "Not Defined" 193 "Not Defined" 192 "Not Defined" 191 "Not Defined" 190 "Not Defined" 189 "Not Defined" 188 "Not Defined" 187 "Not Defined" 186 "Not Defined" 185 "Not Defined" 184 "Not Defined" 183 "Not Defined" 182 "Not Defined" 181 "Not Defined" 180 "Not Defined" 179 "Not Defined" 178 "Not Defined" 177 "Not Defined" 176 "Not Defined" 175 "Not Defined" 174 "Not Defined" 173 "Not Defined" 172 "Not Defined" 171 "Not Defined" 170 "Not Defined" 169 "Not Defined" 168 "Not Defined" 167 "Not Defined" 166 "Not Defined" 165 "Not Defined" 164 "Not Defined" 163 "Not Defined" 162 "Not Defined" 161 "Not Defined" 160 "Not Defined" 159 "Not Defined" 158 "Not Defined" 157 "Not Defined" 156 "Not Defined" 155 "Not Defined" 154 "Not Defined" 153 "Not Defined" 152 "Not Defined" 151 "Not Defined" 150 "Not Defined" 149 "Not Defined" 148 "Not Defined" 147 "Not Defined" 146 "Not Defined" 145 "Not Defined" 144 "Not Defined" 143 "Not Defined" 142 "Not Defined" 141 "Not Defined" 140 "Not Defined" 139 "Not Defined" 138 "Not Defined" 137 "Not Defined" 136 "Not Defined" 135 "Not Defined" 134 "Not Defined" 133 "Not Defined" 132 "Not Defined" 131 "Not Defined" 130 "Not Defined" 129 "Not Defined" 128 "Not Defined" 127 "Not Defined" 126 "Not Defined" 125 "Not Defined" 124 "Not Defined" 123 "Not Defined" 122 "Not Defined" 121 "Not Defined" 120 "Not Defined" 119 "Not Defined" 118 "Not Defined" 117 "Not Defined" 116 "Not Defined" 115 "Not Defined" 114 "Not Defined" 113 "Not Defined" 112 "Not Defined" 111 "Not Defined" 110 "Not Defined" 109 "Not Defined" 108 "Not Defined" 107 "Not Defined" 106 "Not Defined" 105 "Not Defined" 104 "Not Defined" 103 "Not Defined" 102 "Not Defined" 101 "Not Defined" 100 "Not Defined" 99 "Not Defined" 98 "Not Defined" 97 "Not Defined" 96 "Not Defined" 95 "Not Defined" 94 "Not Defined" 93 "Not Defined" 92 "Not Defined" 91 "Not Defined" 90 "Not Defined" 89 "Not Defined" 88 "Not Defined" 87 "Not Defined" 86 "Not Defined" 85 "Not Defined" 84 "Not Defined" 83 "Not Defined" 82 "Not Defined" 81 "Not Defined" 80 "Not Defined" 79 "Not Defined" 78 "Not Defined" 77 "Not Defined" 76 "Not Defined" 75 "Not Defined" 74 "Not Defined" 73 "Not Defined" 72 "Not Defined" 71 "Not Defined" 70 "Not Defined" 69 "Not Defined" 68 "Not Defined" 67 "Not Defined" 66 "Not Defined" 65 "Not Defined" 64 "Not Defined" 63 "Not Defined" 62 "Not Defined" 61 "Not Defined" 60 "Not Defined" 59 "Not Defined" 58 "Not Defined" 57 "Not Defined" 56 "Not Defined" 55 "Not Defined" 54 "Not Defined" 53 "Not Defined" 52 "Not Defined" 51 "Not Defined" 50 "Not Defined" 49 "Not Defined" 48 "Not Defined" 47 "Not Defined" 46 "Not Defined" 45 "Not Defined" 44 "Not Defined" 43 "Not Defined" 42 "Not Defined" 41 "Not Defined" 40 "Not Defined" 39 "Not Defined" 38 "Not Defined" 37 "Not Defined" 36 "Not Defined" 35 "Not Defined" 34 "Not Defined" 33 "High Output On Status Not Define" 32 "High Output Off Status Not Defin" 31 "Not Defined" 30 "Not Defined" 29 "Not Defined" 28 "Not Defined" 27 "Not Defined" 26 "Not Defined" 25 "Not Defined" 24 "Not Defined" 23 "Not Defined" 22 "Not Defined" 21 "Not Defined" 20 "Not Defined" 19 "Not Defined" 18 "Not Defined" 17 "High Output In Status Nok" 16 "High Output Off Status Nok" 15 "High Output Not Available" 14 "Not Defined" 13 "Not Defined" 12 "Not Defined" 11 "Not Defined" 10 "Not Defined" 9 "Not Defined" 8 "Not Defined" 7 "Not Defined" 6 "Not Defined" 5 "Not Defined" 4 "Not Defined" 3 "Not Defined" 2 "Not Defined" 1 "High Output ON Status Ok" 0 "High Output Off Status Ok" ;
VAL_ 2680225568 SHO_Output1 255 "High Output status not available" 254 "High Output status not available" 253 "High Output status not available" 252 "High Output status not available" 251 "High Output status not available" 250 "High Output status not available" 249 "High Output status not available" 248 "High Output status not available" 247 "High Output status not available" 246 "High Output status not available" 245 "High Output status not available" 244 "High Output status not available" 243 "High Output status not available" 242 "High Output status not available" 241 "High Output status not available" 240 "High Output status not available" 239 "Not Defined" 238 "Not Defined" 237 "Not Defined" 236 "Not Defined" 235 "Not Defined" 234 "Not Defined" 233 "Not Defined" 232 "Not Defined" 231 "Not Defined" 230 "Not Defined" 229 "Not Defined" 228 "Not Defined" 227 "Not Defined" 226 "Not Defined" 225 "Not Defined" 224 "Not Defined" 223 "Not Defined" 222 "Not Defined" 221 "Not Defined" 220 "Not Defined" 219 "Not Defined" 218 "Not Defined" 217 "Not Defined" 216 "Not Defined" 215 "Not Defined" 214 "Not Defined" 213 "Not Defined" 212 "Not Defined" 211 "Not Defined" 210 "Not Defined" 209 "Not Defined" 208 "Not Defined" 207 "Not Defined" 206 "Not Defined" 205 "Not Defined" 204 "Not Defined" 203 "Not Defined" 202 "Not Defined" 201 "Not Defined" 200 "Not Defined" 199 "Not Defined" 198 "Not Defined" 197 "Not Defined" 196 "Not Defined" 195 "Not Defined" 194 "Not Defined" 193 "Not Defined" 192 "Not Defined" 191 "Not Defined" 190 "Not Defined" 189 "Not Defined" 188 "Not Defined" 187 "Not Defined" 186 "Not Defined" 185 "Not Defined" 184 "Not Defined" 183 "Not Defined" 182 "Not Defined" 181 "Not Defined" 180 "Not Defined" 179 "Not Defined" 178 "Not Defined" 177 "Not Defined" 176 "Not Defined" 175 "Not Defined" 174 "Not Defined" 173 "Not Defined" 172 "Not Defined" 171 "Not Defined" 170 "Not Defined" 169 "Not Defined" 168 "Not Defined" 167 "Not Defined" 166 "Not Defined" 165 "Not Defined" 164 "Not Defined" 163 "Not Defined" 162 "Not Defined" 161 "Not Defined" 160 "Not Defined" 159 "Not Defined" 158 "Not Defined" 157 "Not Defined" 156 "Not Defined" 155 "Not Defined" 154 "Not Defined" 153 "Not Defined" 152 "Not Defined" 151 "Not Defined" 150 "Not Defined" 149 "Not Defined" 148 "Not Defined" 147 "Not Defined" 146 "Not Defined" 145 "Not Defined" 144 "Not Defined" 143 "Not Defined" 142 "Not Defined" 141 "Not Defined" 140 "Not Defined" 139 "Not Defined" 138 "Not Defined" 137 "Not Defined" 136 "Not Defined" 135 "Not Defined" 134 "Not Defined" 133 "Not Defined" 132 "Not Defined" 131 "Not Defined" 130 "Not Defined" 129 "Not Defined" 128 "Not Defined" 127 "Not Defined" 126 "Not Defined" 125 "Not Defined" 124 "Not Defined" 123 "Not Defined" 122 "Not Defined" 121 "Not Defined" 120 "Not Defined" 119 "Not Defined" 118 "Not Defined" 117 "Not Defined" 116 "Not Defined" 115 "Not Defined" 114 "Not Defined" 113 "Not Defined" 112 "Not Defined" 111 "Not Defined" 110 "Not Defined" 109 "Not Defined" 108 "Not Defined" 107 "Not Defined" 106 "Not Defined" 105 "Not Defined" 104 "Not Defined" 103 "Not Defined" 102 "Not Defined" 101 "Not Defined" 100 "Not Defined" 99 "Not Defined" 98 "Not Defined" 97 "Not Defined" 96 "Not Defined" 95 "Not Defined" 94 "Not Defined" 93 "Not Defined" 92 "Not Defined" 91 "Not Defined" 90 "Not Defined" 89 "Not Defined" 88 "Not Defined" 87 "Not Defined" 86 "Not Defined" 85 "Not Defined" 84 "Not Defined" 83 "Not Defined" 82 "Not Defined" 81 "Not Defined" 80 "Not Defined" 79 "Not Defined" 78 "Not Defined" 77 "Not Defined" 76 "Not Defined" 75 "Not Defined" 74 "Not Defined" 73 "Not Defined" 72 "Not Defined" 71 "Not Defined" 70 "Not Defined" 69 "Not Defined" 68 "Not Defined" 67 "Not Defined" 66 "Not Defined" 65 "Not Defined" 64 "Not Defined" 63 "Not Defined" 62 "Not Defined" 61 "Not Defined" 60 "Not Defined" 59 "Not Defined" 58 "Not Defined" 57 "Not Defined" 56 "Not Defined" 55 "Not Defined" 54 "Not Defined" 53 "Not Defined" 52 "Not Defined" 51 "Not Defined" 50 "Not Defined" 49 "Not Defined" 48 "Not Defined" 47 "Not Defined" 46 "Not Defined" 45 "Not Defined" 44 "Not Defined" 43 "Not Defined" 42 "Not Defined" 41 "Not Defined" 40 "Not Defined" 39 "Not Defined" 38 "Not Defined" 37 "Not Defined" 36 "Not Defined" 35 "Not Defined" 34 "Not Defined" 33 "High Output On Status Not Define" 32 "High Output Off Status Not Defin" 31 "Not Defined" 30 "Not Defined" 29 "Not Defined" 28 "Not Defined" 27 "Not Defined" 26 "Not Defined" 25 "Not Defined" 24 "Not Defined" 23 "Not Defined" 22 "Not Defined" 21 "Not Defined" 20 "Not Defined" 19 "Not Defined" 18 "Not Defined" 17 "High Output In Status Nok" 16 "High Output Off Status Nok" 15 "High Output Not Available" 14 "Not Defined" 13 "Not Defined" 12 "Not Defined" 11 "Not Defined" 10 "Not Defined" 9 "Not Defined" 8 "Not Defined" 7 "Not Defined" 6 "Not Defined" 5 "Not Defined" 4 "Not Defined" 3 "Not Defined" 2 "Not Defined" 1 "High Output ON Status Ok" 0 "High Output Off Status Ok" ;
VAL_ 2680225560 RMO_Output8 255 "Signal Not Available" 254 "Not Defined" 253 "Not Defined" 252 "Not Defined" 251 "Not Defined" 250 "Not Defined" 249 "Not Defined" 248 "Not Defined" 247 "Not Defined" 246 "Not Defined" 245 "Not Defined" 244 "Not Defined" 243 "Not Defined" 242 "Not Defined" 241 "Not Defined" ;
VAL_ 2680225560 RMO_Output7 255 "Signal Not Available" 254 "Not Defined" 253 "Not Defined" 252 "Not Defined" 251 "Not Defined" 250 "Not Defined" 249 "Not Defined" 248 "Not Defined" 247 "Not Defined" 246 "Not Defined" 245 "Not Defined" 244 "Not Defined" 243 "Not Defined" 242 "Not Defined" 241 "Not Defined" ;
VAL_ 2680225560 RMO_Output6 255 "Signal Not Available" 254 "Not Defined" 253 "Not Defined" 252 "Not Defined" 251 "Not Defined" 250 "Not Defined" 249 "Not Defined" 248 "Not Defined" 247 "Not Defined" 246 "Not Defined" 245 "Not Defined" 244 "Not Defined" 243 "Not Defined" 242 "Not Defined" 241 "Not Defined" ;
VAL_ 2680225560 RMO_Output5 255 "Signal Not Available" 254 "Not Defined" 253 "Not Defined" 252 "Not Defined" 251 "Not Defined" 250 "Not Defined" 249 "Not Defined" 248 "Not Defined" 247 "Not Defined" 246 "Not Defined" 245 "Not Defined" 244 "Not Defined" 243 "Not Defined" 242 "Not Defined" 241 "Not Defined" ;
VAL_ 2680225560 RMO_Output4 255 "Signal Not Available" 254 "Not Defined" 253 "Not Defined" 252 "Not Defined" 251 "Not Defined" 250 "Not Defined" 249 "Not Defined" 248 "Not Defined" 247 "Not Defined" 246 "Not Defined" 245 "Not Defined" 244 "Not Defined" 243 "Not Defined" 242 "Not Defined" 241 "Not Defined" ;
VAL_ 2680225560 RMO_Output3 255 "Signal Not Available" 254 "Not Defined" 253 "Not Defined" 252 "Not Defined" 251 "Not Defined" 250 "Not Defined" 249 "Not Defined" 248 "Not Defined" 247 "Not Defined" 246 "Not Defined" 245 "Not Defined" 244 "Not Defined" 243 "Not Defined" 242 "Not Defined" 241 "Not Defined" ;
VAL_ 2680225560 RMO_Output2 255 "Signal Not Available" 254 "Not Defined" 253 "Not Defined" 252 "Not Defined" 251 "Not Defined" 250 "Not Defined" 249 "Not Defined" 248 "Not Defined" 247 "Not Defined" 246 "Not Defined" 245 "Not Defined" 244 "Not Defined" 243 "Not Defined" 242 "Not Defined" 241 "Not Defined" ;
VAL_ 2680225560 RMO_Output1 255 "Signal Not Available" 254 "Not Defined" 253 "Not Defined" 252 "Not Defined" 251 "Not Defined" 250 "Not Defined" 249 "Not Defined" 248 "Not Defined" 247 "Not Defined" 246 "Not Defined" 245 "Not Defined" 244 "Not Defined" 243 "Not Defined" 242 "Not Defined" 241 "Not Defined" ;
VAL_ 2680225553 CMO_Output8 65535 "Signal Not Available" 64510 "Not Defined" 64509 "Not Defined" 64508 "Not Defined" 64507 "Not Defined" 64506 "Not Defined" 64505 "Not Defined" 64504 "Not Defined" 64503 "Not Defined" 64502 "Not Defined" 64501 "Not Defined" 64500 "Not Defined" 64499 "Not Defined" 64498 "Not Defined" 64497 "Not Defined" 64496 "Not Defined" 64495 "Not Defined" 64494 "Not Defined" 64493 "Not Defined" 64492 "Not Defined" 64491 "Not Defined" 64490 "Not Defined" 64489 "Not Defined" 64488 "Not Defined" 64487 "Not Defined" 64486 "Not Defined" 64485 "Not Defined" 64484 "Not Defined" 64483 "Not Defined" 64482 "Not Defined" 64481 "Not Defined" 64480 "Not Defined" 64479 "Not Defined" 64478 "Not Defined" 64477 "Not Defined" 64476 "Not Defined" 64475 "Not Defined" 64474 "Not Defined" 64473 "Not Defined" 64472 "Not Defined" 64471 "Not Defined" 64470 "Not Defined" 64469 "Not Defined" 64468 "Not Defined" 64467 "Not Defined" 64466 "Not Defined" 64465 "Not Defined" 64464 "Not Defined" 64463 "Not Defined" 64462 "Not Defined" 64461 "Not Defined" 64460 "Not Defined" 64459 "Not Defined" 64458 "Not Defined" 64457 "Not Defined" 64456 "Not Defined" 64455 "Not Defined" 64454 "Not Defined" 64453 "Not Defined" 64452 "Not Defined" 64451 "Not Defined" 64450 "Not Defined" 64449 "Not Defined" 64448 "Not Defined" 64447 "Not Defined" 64446 "Not Defined" 64445 "Not Defined" 64444 "Not Defined" 64443 "Not Defined" 64442 "Not Defined" 64441 "Not Defined" 64440 "Not Defined" 64439 "Not Defined" 64438 "Not Defined" 64437 "Not Defined" 64436 "Not Defined" 64435 "Not Defined" 64434 "Not Defined" 64433 "Not Defined" 64432 "Not Defined" 64431 "Not Defined" 64430 "Not Defined" 64429 "Not Defined" 64428 "Not Defined" 64427 "Not Defined" 64426 "Not Defined" 64425 "Not Defined" 64424 "Not Defined" 64423 "Not Defined" 64422 "Not Defined" 64421 "Not Defined" 64420 "Not Defined" 64419 "Not Defined" 64418 "Not Defined" 64417 "Not Defined" 64416 "Not Defined" 64415 "Not Defined" 64414 "Not Defined" 64413 "Not Defined" 64412 "Not Defined" 64411 "Not Defined" 64410 "Not Defined" 64409 "Not Defined" 64408 "Not Defined" 64407 "Not Defined" 64406 "Not Defined" 64405 "Not Defined" 64404 "Not Defined" 64403 "Not Defined" 64402 "Not Defined" 64401 "Not Defined" 64400 "Not Defined" 64399 "Not Defined" 64398 "Not Defined" 64397 "Not Defined" 64396 "Not Defined" 64395 "Not Defined" 64394 "Not Defined" 64393 "Not Defined" 64392 "Not Defined" 64391 "Not Defined" 64390 "Not Defined" 64389 "Not Defined" 64388 "Not Defined" 64387 "Not Defined" 64386 "Not Defined" 64385 "Not Defined" 64384 "Not Defined" 64383 "Not Defined" 64382 "Not Defined" 64381 "Not Defined" 64380 "Not Defined" 64379 "Not Defined" 64378 "Not Defined" 64377 "Not Defined" 64376 "Not Defined" 64375 "Not Defined" 64374 "Not Defined" 64373 "Not Defined" 64372 "Not Defined" 64371 "Not Defined" 64370 "Not Defined" 64369 "Not Defined" 64368 "Not Defined" 64367 "Not Defined" 64366 "Not Defined" 64365 "Not Defined" 64364 "Not Defined" 64363 "Not Defined" 64362 "Not Defined" 64361 "Not Defined" 64360 "Not Defined" 64359 "Not Defined" 64358 "Not Defined" 64357 "Not Defined" 64356 "Not Defined" 64355 "Not Defined" 64354 "Not Defined" 64353 "Not Defined" 64352 "Not Defined" 64351 "Not Defined" 64350 "Not Defined" 64349 "Not Defined" 64348 "Not Defined" 64347 "Not Defined" 64346 "Not Defined" 64345 "Not Defined" 64344 "Not Defined" 64343 "Not Defined" 64342 "Not Defined" 64341 "Not Defined" 64340 "Not Defined" 64339 "Not Defined" 64338 "Not Defined" 64337 "Not Defined" 64336 "Not Defined" 64335 "Not Defined" 64334 "Not Defined" 64333 "Not Defined" 64332 "Not Defined" 64331 "Not Defined" 64330 "Not Defined" 64329 "Not Defined" 64328 "Not Defined" 64327 "Not Defined" 64326 "Not Defined" 64325 "Not Defined" 64324 "Not Defined" 64323 "Not Defined" 64322 "Not Defined" 64321 "Not Defined" 64320 "Not Defined" 64319 "Not Defined" 64318 "Not Defined" 64317 "Not Defined" 64316 "Not Defined" 64315 "Not Defined" 64314 "Not Defined" 64313 "Not Defined" 64312 "Not Defined" 64311 "Not Defined" 64310 "Not Defined" 64309 "Not Defined" 64308 "Not Defined" 64307 "Not Defined" 64306 "Not Defined" 64305 "Not Defined" 64304 "Not Defined" 64303 "Not Defined" 64302 "Not Defined" 64301 "Not Defined" 64300 "Not Defined" 64299 "Not Defined" 64298 "Not Defined" 64297 "Not Defined" 64296 "Not Defined" 64295 "Not Defined" 64294 "Not Defined" 64293 "Not Defined" 64292 "Not Defined" 64291 "Not Defined" 64290 "Not Defined" 64289 "Not Defined" 64288 "Not Defined" 64287 "Not Defined" 64286 "Not Defined" 64285 "Not Defined" 64284 "Not Defined" 64283 "Not Defined" 64282 "Not Defined" 64281 "Not Defined" 64280 "Not Defined" 64279 "Not Defined" 64278 "Not Defined" 64277 "Not Defined" 64276 "Not Defined" 64275 "Not Defined" 64274 "Not Defined" 64273 "Not Defined" 64272 "Not Defined" 64271 "Not Defined" 64270 "Not Defined" 64269 "Not Defined" 64268 "Not Defined" 64267 "Not Defined" 64266 "Not Defined" 64265 "Not Defined" 64264 "Not Defined" 64263 "Not Defined" 64262 "Not Defined" 64261 "Not Defined" 64260 "Not Defined" 64259 "Not Defined" 64258 "Not Defined" 64257 "Not Defined" 64256 "Not Defined" ;
VAL_ 2680225553 CMO_Output7 65535 "Signal Not Available" 64510 "Not Defined" 64509 "Not Defined" 64508 "Not Defined" 64507 "Not Defined" 64506 "Not Defined" 64505 "Not Defined" 64504 "Not Defined" 64503 "Not Defined" 64502 "Not Defined" 64501 "Not Defined" 64500 "Not Defined" 64499 "Not Defined" 64498 "Not Defined" 64497 "Not Defined" 64496 "Not Defined" 64495 "Not Defined" 64494 "Not Defined" 64493 "Not Defined" 64492 "Not Defined" 64491 "Not Defined" 64490 "Not Defined" 64489 "Not Defined" 64488 "Not Defined" 64487 "Not Defined" 64486 "Not Defined" 64485 "Not Defined" 64484 "Not Defined" 64483 "Not Defined" 64482 "Not Defined" 64481 "Not Defined" 64480 "Not Defined" 64479 "Not Defined" 64478 "Not Defined" 64477 "Not Defined" 64476 "Not Defined" 64475 "Not Defined" 64474 "Not Defined" 64473 "Not Defined" 64472 "Not Defined" 64471 "Not Defined" 64470 "Not Defined" 64469 "Not Defined" 64468 "Not Defined" 64467 "Not Defined" 64466 "Not Defined" 64465 "Not Defined" 64464 "Not Defined" 64463 "Not Defined" 64462 "Not Defined" 64461 "Not Defined" 64460 "Not Defined" 64459 "Not Defined" 64458 "Not Defined" 64457 "Not Defined" 64456 "Not Defined" 64455 "Not Defined" 64454 "Not Defined" 64453 "Not Defined" 64452 "Not Defined" 64451 "Not Defined" 64450 "Not Defined" 64449 "Not Defined" 64448 "Not Defined" 64447 "Not Defined" 64446 "Not Defined" 64445 "Not Defined" 64444 "Not Defined" 64443 "Not Defined" 64442 "Not Defined" 64441 "Not Defined" 64440 "Not Defined" 64439 "Not Defined" 64438 "Not Defined" 64437 "Not Defined" 64436 "Not Defined" 64435 "Not Defined" 64434 "Not Defined" 64433 "Not Defined" 64432 "Not Defined" 64431 "Not Defined" 64430 "Not Defined" 64429 "Not Defined" 64428 "Not Defined" 64427 "Not Defined" 64426 "Not Defined" 64425 "Not Defined" 64424 "Not Defined" 64423 "Not Defined" 64422 "Not Defined" 64421 "Not Defined" 64420 "Not Defined" 64419 "Not Defined" 64418 "Not Defined" 64417 "Not Defined" 64416 "Not Defined" 64415 "Not Defined" 64414 "Not Defined" 64413 "Not Defined" 64412 "Not Defined" 64411 "Not Defined" 64410 "Not Defined" 64409 "Not Defined" 64408 "Not Defined" 64407 "Not Defined" 64406 "Not Defined" 64405 "Not Defined" 64404 "Not Defined" 64403 "Not Defined" 64402 "Not Defined" 64401 "Not Defined" 64400 "Not Defined" 64399 "Not Defined" 64398 "Not Defined" 64397 "Not Defined" 64396 "Not Defined" 64395 "Not Defined" 64394 "Not Defined" 64393 "Not Defined" 64392 "Not Defined" 64391 "Not Defined" 64390 "Not Defined" 64389 "Not Defined" 64388 "Not Defined" 64387 "Not Defined" 64386 "Not Defined" 64385 "Not Defined" 64384 "Not Defined" 64383 "Not Defined" 64382 "Not Defined" 64381 "Not Defined" 64380 "Not Defined" 64379 "Not Defined" 64378 "Not Defined" 64377 "Not Defined" 64376 "Not Defined" 64375 "Not Defined" 64374 "Not Defined" 64373 "Not Defined" 64372 "Not Defined" 64371 "Not Defined" 64370 "Not Defined" 64369 "Not Defined" 64368 "Not Defined" 64367 "Not Defined" 64366 "Not Defined" 64365 "Not Defined" 64364 "Not Defined" 64363 "Not Defined" 64362 "Not Defined" 64361 "Not Defined" 64360 "Not Defined" 64359 "Not Defined" 64358 "Not Defined" 64357 "Not Defined" 64356 "Not Defined" 64355 "Not Defined" 64354 "Not Defined" 64353 "Not Defined" 64352 "Not Defined" 64351 "Not Defined" 64350 "Not Defined" 64349 "Not Defined" 64348 "Not Defined" 64347 "Not Defined" 64346 "Not Defined" 64345 "Not Defined" 64344 "Not Defined" 64343 "Not Defined" 64342 "Not Defined" 64341 "Not Defined" 64340 "Not Defined" 64339 "Not Defined" 64338 "Not Defined" 64337 "Not Defined" 64336 "Not Defined" 64335 "Not Defined" 64334 "Not Defined" 64333 "Not Defined" 64332 "Not Defined" 64331 "Not Defined" 64330 "Not Defined" 64329 "Not Defined" 64328 "Not Defined" 64327 "Not Defined" 64326 "Not Defined" 64325 "Not Defined" 64324 "Not Defined" 64323 "Not Defined" 64322 "Not Defined" 64321 "Not Defined" 64320 "Not Defined" 64319 "Not Defined" 64318 "Not Defined" 64317 "Not Defined" 64316 "Not Defined" 64315 "Not Defined" 64314 "Not Defined" 64313 "Not Defined" 64312 "Not Defined" 64311 "Not Defined" 64310 "Not Defined" 64309 "Not Defined" 64308 "Not Defined" 64307 "Not Defined" 64306 "Not Defined" 64305 "Not Defined" 64304 "Not Defined" 64303 "Not Defined" 64302 "Not Defined" 64301 "Not Defined" 64300 "Not Defined" 64299 "Not Defined" 64298 "Not Defined" 64297 "Not Defined" 64296 "Not Defined" 64295 "Not Defined" 64294 "Not Defined" 64293 "Not Defined" 64292 "Not Defined" 64291 "Not Defined" 64290 "Not Defined" 64289 "Not Defined" 64288 "Not Defined" 64287 "Not Defined" 64286 "Not Defined" 64285 "Not Defined" 64284 "Not Defined" 64283 "Not Defined" 64282 "Not Defined" 64281 "Not Defined" 64280 "Not Defined" 64279 "Not Defined" 64278 "Not Defined" 64277 "Not Defined" 64276 "Not Defined" 64275 "Not Defined" 64274 "Not Defined" 64273 "Not Defined" 64272 "Not Defined" 64271 "Not Defined" 64270 "Not Defined" 64269 "Not Defined" 64268 "Not Defined" 64267 "Not Defined" 64266 "Not Defined" 64265 "Not Defined" 64264 "Not Defined" 64263 "Not Defined" 64262 "Not Defined" 64261 "Not Defined" 64260 "Not Defined" 64259 "Not Defined" 64258 "Not Defined" 64257 "Not Defined" 64256 "Not Defined" ;
VAL_ 2680225553 CMO_Output6 65535 "Signal Not Available" 64510 "Not Defined" 64509 "Not Defined" 64508 "Not Defined" 64507 "Not Defined" 64506 "Not Defined" 64505 "Not Defined" 64504 "Not Defined" 64503 "Not Defined" 64502 "Not Defined" 64501 "Not Defined" 64500 "Not Defined" 64499 "Not Defined" 64498 "Not Defined" 64497 "Not Defined" 64496 "Not Defined" 64495 "Not Defined" 64494 "Not Defined" 64493 "Not Defined" 64492 "Not Defined" 64491 "Not Defined" 64490 "Not Defined" 64489 "Not Defined" 64488 "Not Defined" 64487 "Not Defined" 64486 "Not Defined" 64485 "Not Defined" 64484 "Not Defined" 64483 "Not Defined" 64482 "Not Defined" 64481 "Not Defined" 64480 "Not Defined" 64479 "Not Defined" 64478 "Not Defined" 64477 "Not Defined" 64476 "Not Defined" 64475 "Not Defined" 64474 "Not Defined" 64473 "Not Defined" 64472 "Not Defined" 64471 "Not Defined" 64470 "Not Defined" 64469 "Not Defined" 64468 "Not Defined" 64467 "Not Defined" 64466 "Not Defined" 64465 "Not Defined" 64464 "Not Defined" 64463 "Not Defined" 64462 "Not Defined" 64461 "Not Defined" 64460 "Not Defined" 64459 "Not Defined" 64458 "Not Defined" 64457 "Not Defined" 64456 "Not Defined" 64455 "Not Defined" 64454 "Not Defined" 64453 "Not Defined" 64452 "Not Defined" 64451 "Not Defined" 64450 "Not Defined" 64449 "Not Defined" 64448 "Not Defined" 64447 "Not Defined" 64446 "Not Defined" 64445 "Not Defined" 64444 "Not Defined" 64443 "Not Defined" 64442 "Not Defined" 64441 "Not Defined" 64440 "Not Defined" 64439 "Not Defined" 64438 "Not Defined" 64437 "Not Defined" 64436 "Not Defined" 64435 "Not Defined" 64434 "Not Defined" 64433 "Not Defined" 64432 "Not Defined" 64431 "Not Defined" 64430 "Not Defined" 64429 "Not Defined" 64428 "Not Defined" 64427 "Not Defined" 64426 "Not Defined" 64425 "Not Defined" 64424 "Not Defined" 64423 "Not Defined" 64422 "Not Defined" 64421 "Not Defined" 64420 "Not Defined" 64419 "Not Defined" 64418 "Not Defined" 64417 "Not Defined" 64416 "Not Defined" 64415 "Not Defined" 64414 "Not Defined" 64413 "Not Defined" 64412 "Not Defined" 64411 "Not Defined" 64410 "Not Defined" 64409 "Not Defined" 64408 "Not Defined" 64407 "Not Defined" 64406 "Not Defined" 64405 "Not Defined" 64404 "Not Defined" 64403 "Not Defined" 64402 "Not Defined" 64401 "Not Defined" 64400 "Not Defined" 64399 "Not Defined" 64398 "Not Defined" 64397 "Not Defined" 64396 "Not Defined" 64395 "Not Defined" 64394 "Not Defined" 64393 "Not Defined" 64392 "Not Defined" 64391 "Not Defined" 64390 "Not Defined" 64389 "Not Defined" 64388 "Not Defined" 64387 "Not Defined" 64386 "Not Defined" 64385 "Not Defined" 64384 "Not Defined" 64383 "Not Defined" 64382 "Not Defined" 64381 "Not Defined" 64380 "Not Defined" 64379 "Not Defined" 64378 "Not Defined" 64377 "Not Defined" 64376 "Not Defined" 64375 "Not Defined" 64374 "Not Defined" 64373 "Not Defined" 64372 "Not Defined" 64371 "Not Defined" 64370 "Not Defined" 64369 "Not Defined" 64368 "Not Defined" 64367 "Not Defined" 64366 "Not Defined" 64365 "Not Defined" 64364 "Not Defined" 64363 "Not Defined" 64362 "Not Defined" 64361 "Not Defined" 64360 "Not Defined" 64359 "Not Defined" 64358 "Not Defined" 64357 "Not Defined" 64356 "Not Defined" 64355 "Not Defined" 64354 "Not Defined" 64353 "Not Defined" 64352 "Not Defined" 64351 "Not Defined" 64350 "Not Defined" 64349 "Not Defined" 64348 "Not Defined" 64347 "Not Defined" 64346 "Not Defined" 64345 "Not Defined" 64344 "Not Defined" 64343 "Not Defined" 64342 "Not Defined" 64341 "Not Defined" 64340 "Not Defined" 64339 "Not Defined" 64338 "Not Defined" 64337 "Not Defined" 64336 "Not Defined" 64335 "Not Defined" 64334 "Not Defined" 64333 "Not Defined" 64332 "Not Defined" 64331 "Not Defined" 64330 "Not Defined" 64329 "Not Defined" 64328 "Not Defined" 64327 "Not Defined" 64326 "Not Defined" 64325 "Not Defined" 64324 "Not Defined" 64323 "Not Defined" 64322 "Not Defined" 64321 "Not Defined" 64320 "Not Defined" 64319 "Not Defined" 64318 "Not Defined" 64317 "Not Defined" 64316 "Not Defined" 64315 "Not Defined" 64314 "Not Defined" 64313 "Not Defined" 64312 "Not Defined" 64311 "Not Defined" 64310 "Not Defined" 64309 "Not Defined" 64308 "Not Defined" 64307 "Not Defined" 64306 "Not Defined" 64305 "Not Defined" 64304 "Not Defined" 64303 "Not Defined" 64302 "Not Defined" 64301 "Not Defined" 64300 "Not Defined" 64299 "Not Defined" 64298 "Not Defined" 64297 "Not Defined" 64296 "Not Defined" 64295 "Not Defined" 64294 "Not Defined" 64293 "Not Defined" 64292 "Not Defined" 64291 "Not Defined" 64290 "Not Defined" 64289 "Not Defined" 64288 "Not Defined" 64287 "Not Defined" 64286 "Not Defined" 64285 "Not Defined" 64284 "Not Defined" 64283 "Not Defined" 64282 "Not Defined" 64281 "Not Defined" 64280 "Not Defined" 64279 "Not Defined" 64278 "Not Defined" 64277 "Not Defined" 64276 "Not Defined" 64275 "Not Defined" 64274 "Not Defined" 64273 "Not Defined" 64272 "Not Defined" 64271 "Not Defined" 64270 "Not Defined" 64269 "Not Defined" 64268 "Not Defined" 64267 "Not Defined" 64266 "Not Defined" 64265 "Not Defined" 64264 "Not Defined" 64263 "Not Defined" 64262 "Not Defined" 64261 "Not Defined" 64260 "Not Defined" 64259 "Not Defined" 64258 "Not Defined" 64257 "Not Defined" 64256 "Not Defined" ;
VAL_ 2680225553 CMO_Output5 65535 "Signal Not Available" 64510 "Not Defined" 64509 "Not Defined" 64508 "Not Defined" 64507 "Not Defined" 64506 "Not Defined" 64505 "Not Defined" 64504 "Not Defined" 64503 "Not Defined" 64502 "Not Defined" 64501 "Not Defined" 64500 "Not Defined" 64499 "Not Defined" 64498 "Not Defined" 64497 "Not Defined" 64496 "Not Defined" 64495 "Not Defined" 64494 "Not Defined" 64493 "Not Defined" 64492 "Not Defined" 64491 "Not Defined" 64490 "Not Defined" 64489 "Not Defined" 64488 "Not Defined" 64487 "Not Defined" 64486 "Not Defined" 64485 "Not Defined" 64484 "Not Defined" 64483 "Not Defined" 64482 "Not Defined" 64481 "Not Defined" 64480 "Not Defined" 64479 "Not Defined" 64478 "Not Defined" 64477 "Not Defined" 64476 "Not Defined" 64475 "Not Defined" 64474 "Not Defined" 64473 "Not Defined" 64472 "Not Defined" 64471 "Not Defined" 64470 "Not Defined" 64469 "Not Defined" 64468 "Not Defined" 64467 "Not Defined" 64466 "Not Defined" 64465 "Not Defined" 64464 "Not Defined" 64463 "Not Defined" 64462 "Not Defined" 64461 "Not Defined" 64460 "Not Defined" 64459 "Not Defined" 64458 "Not Defined" 64457 "Not Defined" 64456 "Not Defined" 64455 "Not Defined" 64454 "Not Defined" 64453 "Not Defined" 64452 "Not Defined" 64451 "Not Defined" 64450 "Not Defined" 64449 "Not Defined" 64448 "Not Defined" 64447 "Not Defined" 64446 "Not Defined" 64445 "Not Defined" 64444 "Not Defined" 64443 "Not Defined" 64442 "Not Defined" 64441 "Not Defined" 64440 "Not Defined" 64439 "Not Defined" 64438 "Not Defined" 64437 "Not Defined" 64436 "Not Defined" 64435 "Not Defined" 64434 "Not Defined" 64433 "Not Defined" 64432 "Not Defined" 64431 "Not Defined" 64430 "Not Defined" 64429 "Not Defined" 64428 "Not Defined" 64427 "Not Defined" 64426 "Not Defined" 64425 "Not Defined" 64424 "Not Defined" 64423 "Not Defined" 64422 "Not Defined" 64421 "Not Defined" 64420 "Not Defined" 64419 "Not Defined" 64418 "Not Defined" 64417 "Not Defined" 64416 "Not Defined" 64415 "Not Defined" 64414 "Not Defined" 64413 "Not Defined" 64412 "Not Defined" 64411 "Not Defined" 64410 "Not Defined" 64409 "Not Defined" 64408 "Not Defined" 64407 "Not Defined" 64406 "Not Defined" 64405 "Not Defined" 64404 "Not Defined" 64403 "Not Defined" 64402 "Not Defined" 64401 "Not Defined" 64400 "Not Defined" 64399 "Not Defined" 64398 "Not Defined" 64397 "Not Defined" 64396 "Not Defined" 64395 "Not Defined" 64394 "Not Defined" 64393 "Not Defined" 64392 "Not Defined" 64391 "Not Defined" 64390 "Not Defined" 64389 "Not Defined" 64388 "Not Defined" 64387 "Not Defined" 64386 "Not Defined" 64385 "Not Defined" 64384 "Not Defined" 64383 "Not Defined" 64382 "Not Defined" 64381 "Not Defined" 64380 "Not Defined" 64379 "Not Defined" 64378 "Not Defined" 64377 "Not Defined" 64376 "Not Defined" 64375 "Not Defined" 64374 "Not Defined" 64373 "Not Defined" 64372 "Not Defined" 64371 "Not Defined" 64370 "Not Defined" 64369 "Not Defined" 64368 "Not Defined" 64367 "Not Defined" 64366 "Not Defined" 64365 "Not Defined" 64364 "Not Defined" 64363 "Not Defined" 64362 "Not Defined" 64361 "Not Defined" 64360 "Not Defined" 64359 "Not Defined" 64358 "Not Defined" 64357 "Not Defined" 64356 "Not Defined" 64355 "Not Defined" 64354 "Not Defined" 64353 "Not Defined" 64352 "Not Defined" 64351 "Not Defined" 64350 "Not Defined" 64349 "Not Defined" 64348 "Not Defined" 64347 "Not Defined" 64346 "Not Defined" 64345 "Not Defined" 64344 "Not Defined" 64343 "Not Defined" 64342 "Not Defined" 64341 "Not Defined" 64340 "Not Defined" 64339 "Not Defined" 64338 "Not Defined" 64337 "Not Defined" 64336 "Not Defined" 64335 "Not Defined" 64334 "Not Defined" 64333 "Not Defined" 64332 "Not Defined" 64331 "Not Defined" 64330 "Not Defined" 64329 "Not Defined" 64328 "Not Defined" 64327 "Not Defined" 64326 "Not Defined" 64325 "Not Defined" 64324 "Not Defined" 64323 "Not Defined" 64322 "Not Defined" 64321 "Not Defined" 64320 "Not Defined" 64319 "Not Defined" 64318 "Not Defined" 64317 "Not Defined" 64316 "Not Defined" 64315 "Not Defined" 64314 "Not Defined" 64313 "Not Defined" 64312 "Not Defined" 64311 "Not Defined" 64310 "Not Defined" 64309 "Not Defined" 64308 "Not Defined" 64307 "Not Defined" 64306 "Not Defined" 64305 "Not Defined" 64304 "Not Defined" 64303 "Not Defined" 64302 "Not Defined" 64301 "Not Defined" 64300 "Not Defined" 64299 "Not Defined" 64298 "Not Defined" 64297 "Not Defined" 64296 "Not Defined" 64295 "Not Defined" 64294 "Not Defined" 64293 "Not Defined" 64292 "Not Defined" 64291 "Not Defined" 64290 "Not Defined" 64289 "Not Defined" 64288 "Not Defined" 64287 "Not Defined" 64286 "Not Defined" 64285 "Not Defined" 64284 "Not Defined" 64283 "Not Defined" 64282 "Not Defined" 64281 "Not Defined" 64280 "Not Defined" 64279 "Not Defined" 64278 "Not Defined" 64277 "Not Defined" 64276 "Not Defined" 64275 "Not Defined" 64274 "Not Defined" 64273 "Not Defined" 64272 "Not Defined" 64271 "Not Defined" 64270 "Not Defined" 64269 "Not Defined" 64268 "Not Defined" 64267 "Not Defined" 64266 "Not Defined" 64265 "Not Defined" 64264 "Not Defined" 64263 "Not Defined" 64262 "Not Defined" 64261 "Not Defined" 64260 "Not Defined" 64259 "Not Defined" 64258 "Not Defined" 64257 "Not Defined" 64256 "Not Defined" ;
VAL_ 2680225552 CMO_Output4 65535 "Signal Not Available" 64510 "Not Defined" 64509 "Not Defined" 64508 "Not Defined" 64507 "Not Defined" 64506 "Not Defined" 64505 "Not Defined" 64504 "Not Defined" 64503 "Not Defined" 64502 "Not Defined" 64501 "Not Defined" 64500 "Not Defined" 64499 "Not Defined" 64498 "Not Defined" 64497 "Not Defined" 64496 "Not Defined" 64495 "Not Defined" 64494 "Not Defined" 64493 "Not Defined" 64492 "Not Defined" 64491 "Not Defined" 64490 "Not Defined" 64489 "Not Defined" 64488 "Not Defined" 64487 "Not Defined" 64486 "Not Defined" 64485 "Not Defined" 64484 "Not Defined" 64483 "Not Defined" 64482 "Not Defined" 64481 "Not Defined" 64480 "Not Defined" 64479 "Not Defined" 64478 "Not Defined" 64477 "Not Defined" 64476 "Not Defined" 64475 "Not Defined" 64474 "Not Defined" 64473 "Not Defined" 64472 "Not Defined" 64471 "Not Defined" 64470 "Not Defined" 64469 "Not Defined" 64468 "Not Defined" 64467 "Not Defined" 64466 "Not Defined" 64465 "Not Defined" 64464 "Not Defined" 64463 "Not Defined" 64462 "Not Defined" 64461 "Not Defined" 64460 "Not Defined" 64459 "Not Defined" 64458 "Not Defined" 64457 "Not Defined" 64456 "Not Defined" 64455 "Not Defined" 64454 "Not Defined" 64453 "Not Defined" 64452 "Not Defined" 64451 "Not Defined" 64450 "Not Defined" 64449 "Not Defined" 64448 "Not Defined" 64447 "Not Defined" 64446 "Not Defined" 64445 "Not Defined" 64444 "Not Defined" 64443 "Not Defined" 64442 "Not Defined" 64441 "Not Defined" 64440 "Not Defined" 64439 "Not Defined" 64438 "Not Defined" 64437 "Not Defined" 64436 "Not Defined" 64435 "Not Defined" 64434 "Not Defined" 64433 "Not Defined" 64432 "Not Defined" 64431 "Not Defined" 64430 "Not Defined" 64429 "Not Defined" 64428 "Not Defined" 64427 "Not Defined" 64426 "Not Defined" 64425 "Not Defined" 64424 "Not Defined" 64423 "Not Defined" 64422 "Not Defined" 64421 "Not Defined" 64420 "Not Defined" 64419 "Not Defined" 64418 "Not Defined" 64417 "Not Defined" 64416 "Not Defined" 64415 "Not Defined" 64414 "Not Defined" 64413 "Not Defined" 64412 "Not Defined" 64411 "Not Defined" 64410 "Not Defined" 64409 "Not Defined" 64408 "Not Defined" 64407 "Not Defined" 64406 "Not Defined" 64405 "Not Defined" 64404 "Not Defined" 64403 "Not Defined" 64402 "Not Defined" 64401 "Not Defined" 64400 "Not Defined" 64399 "Not Defined" 64398 "Not Defined" 64397 "Not Defined" 64396 "Not Defined" 64395 "Not Defined" 64394 "Not Defined" 64393 "Not Defined" 64392 "Not Defined" 64391 "Not Defined" 64390 "Not Defined" 64389 "Not Defined" 64388 "Not Defined" 64387 "Not Defined" 64386 "Not Defined" 64385 "Not Defined" 64384 "Not Defined" 64383 "Not Defined" 64382 "Not Defined" 64381 "Not Defined" 64380 "Not Defined" 64379 "Not Defined" 64378 "Not Defined" 64377 "Not Defined" 64376 "Not Defined" 64375 "Not Defined" 64374 "Not Defined" 64373 "Not Defined" 64372 "Not Defined" 64371 "Not Defined" 64370 "Not Defined" 64369 "Not Defined" 64368 "Not Defined" 64367 "Not Defined" 64366 "Not Defined" 64365 "Not Defined" 64364 "Not Defined" 64363 "Not Defined" 64362 "Not Defined" 64361 "Not Defined" 64360 "Not Defined" 64359 "Not Defined" 64358 "Not Defined" 64357 "Not Defined" 64356 "Not Defined" 64355 "Not Defined" 64354 "Not Defined" 64353 "Not Defined" 64352 "Not Defined" 64351 "Not Defined" 64350 "Not Defined" 64349 "Not Defined" 64348 "Not Defined" 64347 "Not Defined" 64346 "Not Defined" 64345 "Not Defined" 64344 "Not Defined" 64343 "Not Defined" 64342 "Not Defined" 64341 "Not Defined" 64340 "Not Defined" 64339 "Not Defined" 64338 "Not Defined" 64337 "Not Defined" 64336 "Not Defined" 64335 "Not Defined" 64334 "Not Defined" 64333 "Not Defined" 64332 "Not Defined" 64331 "Not Defined" 64330 "Not Defined" 64329 "Not Defined" 64328 "Not Defined" 64327 "Not Defined" 64326 "Not Defined" 64325 "Not Defined" 64324 "Not Defined" 64323 "Not Defined" 64322 "Not Defined" 64321 "Not Defined" 64320 "Not Defined" 64319 "Not Defined" 64318 "Not Defined" 64317 "Not Defined" 64316 "Not Defined" 64315 "Not Defined" 64314 "Not Defined" 64313 "Not Defined" 64312 "Not Defined" 64311 "Not Defined" 64310 "Not Defined" 64309 "Not Defined" 64308 "Not Defined" 64307 "Not Defined" 64306 "Not Defined" 64305 "Not Defined" 64304 "Not Defined" 64303 "Not Defined" 64302 "Not Defined" 64301 "Not Defined" 64300 "Not Defined" 64299 "Not Defined" 64298 "Not Defined" 64297 "Not Defined" 64296 "Not Defined" 64295 "Not Defined" 64294 "Not Defined" 64293 "Not Defined" 64292 "Not Defined" 64291 "Not Defined" 64290 "Not Defined" 64289 "Not Defined" 64288 "Not Defined" 64287 "Not Defined" 64286 "Not Defined" 64285 "Not Defined" 64284 "Not Defined" 64283 "Not Defined" 64282 "Not Defined" 64281 "Not Defined" 64280 "Not Defined" 64279 "Not Defined" 64278 "Not Defined" 64277 "Not Defined" 64276 "Not Defined" 64275 "Not Defined" 64274 "Not Defined" 64273 "Not Defined" 64272 "Not Defined" 64271 "Not Defined" 64270 "Not Defined" 64269 "Not Defined" 64268 "Not Defined" 64267 "Not Defined" 64266 "Not Defined" 64265 "Not Defined" 64264 "Not Defined" 64263 "Not Defined" 64262 "Not Defined" 64261 "Not Defined" 64260 "Not Defined" 64259 "Not Defined" 64258 "Not Defined" 64257 "Not Defined" 64256 "Not Defined" ;
VAL_ 2680225552 CMO_Output3 65535 "Signal Not Available" 64510 "Not Defined" 64509 "Not Defined" 64508 "Not Defined" 64507 "Not Defined" 64506 "Not Defined" 64505 "Not Defined" 64504 "Not Defined" 64503 "Not Defined" 64502 "Not Defined" 64501 "Not Defined" 64500 "Not Defined" 64499 "Not Defined" 64498 "Not Defined" 64497 "Not Defined" 64496 "Not Defined" 64495 "Not Defined" 64494 "Not Defined" 64493 "Not Defined" 64492 "Not Defined" 64491 "Not Defined" 64490 "Not Defined" 64489 "Not Defined" 64488 "Not Defined" 64487 "Not Defined" 64486 "Not Defined" 64485 "Not Defined" 64484 "Not Defined" 64483 "Not Defined" 64482 "Not Defined" 64481 "Not Defined" 64480 "Not Defined" 64479 "Not Defined" 64478 "Not Defined" 64477 "Not Defined" 64476 "Not Defined" 64475 "Not Defined" 64474 "Not Defined" 64473 "Not Defined" 64472 "Not Defined" 64471 "Not Defined" 64470 "Not Defined" 64469 "Not Defined" 64468 "Not Defined" 64467 "Not Defined" 64466 "Not Defined" 64465 "Not Defined" 64464 "Not Defined" 64463 "Not Defined" 64462 "Not Defined" 64461 "Not Defined" 64460 "Not Defined" 64459 "Not Defined" 64458 "Not Defined" 64457 "Not Defined" 64456 "Not Defined" 64455 "Not Defined" 64454 "Not Defined" 64453 "Not Defined" 64452 "Not Defined" 64451 "Not Defined" 64450 "Not Defined" 64449 "Not Defined" 64448 "Not Defined" 64447 "Not Defined" 64446 "Not Defined" 64445 "Not Defined" 64444 "Not Defined" 64443 "Not Defined" 64442 "Not Defined" 64441 "Not Defined" 64440 "Not Defined" 64439 "Not Defined" 64438 "Not Defined" 64437 "Not Defined" 64436 "Not Defined" 64435 "Not Defined" 64434 "Not Defined" 64433 "Not Defined" 64432 "Not Defined" 64431 "Not Defined" 64430 "Not Defined" 64429 "Not Defined" 64428 "Not Defined" 64427 "Not Defined" 64426 "Not Defined" 64425 "Not Defined" 64424 "Not Defined" 64423 "Not Defined" 64422 "Not Defined" 64421 "Not Defined" 64420 "Not Defined" 64419 "Not Defined" 64418 "Not Defined" 64417 "Not Defined" 64416 "Not Defined" 64415 "Not Defined" 64414 "Not Defined" 64413 "Not Defined" 64412 "Not Defined" 64411 "Not Defined" 64410 "Not Defined" 64409 "Not Defined" 64408 "Not Defined" 64407 "Not Defined" 64406 "Not Defined" 64405 "Not Defined" 64404 "Not Defined" 64403 "Not Defined" 64402 "Not Defined" 64401 "Not Defined" 64400 "Not Defined" 64399 "Not Defined" 64398 "Not Defined" 64397 "Not Defined" 64396 "Not Defined" 64395 "Not Defined" 64394 "Not Defined" 64393 "Not Defined" 64392 "Not Defined" 64391 "Not Defined" 64390 "Not Defined" 64389 "Not Defined" 64388 "Not Defined" 64387 "Not Defined" 64386 "Not Defined" 64385 "Not Defined" 64384 "Not Defined" 64383 "Not Defined" 64382 "Not Defined" 64381 "Not Defined" 64380 "Not Defined" 64379 "Not Defined" 64378 "Not Defined" 64377 "Not Defined" 64376 "Not Defined" 64375 "Not Defined" 64374 "Not Defined" 64373 "Not Defined" 64372 "Not Defined" 64371 "Not Defined" 64370 "Not Defined" 64369 "Not Defined" 64368 "Not Defined" 64367 "Not Defined" 64366 "Not Defined" 64365 "Not Defined" 64364 "Not Defined" 64363 "Not Defined" 64362 "Not Defined" 64361 "Not Defined" 64360 "Not Defined" 64359 "Not Defined" 64358 "Not Defined" 64357 "Not Defined" 64356 "Not Defined" 64355 "Not Defined" 64354 "Not Defined" 64353 "Not Defined" 64352 "Not Defined" 64351 "Not Defined" 64350 "Not Defined" 64349 "Not Defined" 64348 "Not Defined" 64347 "Not Defined" 64346 "Not Defined" 64345 "Not Defined" 64344 "Not Defined" 64343 "Not Defined" 64342 "Not Defined" 64341 "Not Defined" 64340 "Not Defined" 64339 "Not Defined" 64338 "Not Defined" 64337 "Not Defined" 64336 "Not Defined" 64335 "Not Defined" 64334 "Not Defined" 64333 "Not Defined" 64332 "Not Defined" 64331 "Not Defined" 64330 "Not Defined" 64329 "Not Defined" 64328 "Not Defined" 64327 "Not Defined" 64326 "Not Defined" 64325 "Not Defined" 64324 "Not Defined" 64323 "Not Defined" 64322 "Not Defined" 64321 "Not Defined" 64320 "Not Defined" 64319 "Not Defined" 64318 "Not Defined" 64317 "Not Defined" 64316 "Not Defined" 64315 "Not Defined" 64314 "Not Defined" 64313 "Not Defined" 64312 "Not Defined" 64311 "Not Defined" 64310 "Not Defined" 64309 "Not Defined" 64308 "Not Defined" 64307 "Not Defined" 64306 "Not Defined" 64305 "Not Defined" 64304 "Not Defined" 64303 "Not Defined" 64302 "Not Defined" 64301 "Not Defined" 64300 "Not Defined" 64299 "Not Defined" 64298 "Not Defined" 64297 "Not Defined" 64296 "Not Defined" 64295 "Not Defined" 64294 "Not Defined" 64293 "Not Defined" 64292 "Not Defined" 64291 "Not Defined" 64290 "Not Defined" 64289 "Not Defined" 64288 "Not Defined" 64287 "Not Defined" 64286 "Not Defined" 64285 "Not Defined" 64284 "Not Defined" 64283 "Not Defined" 64282 "Not Defined" 64281 "Not Defined" 64280 "Not Defined" 64279 "Not Defined" 64278 "Not Defined" 64277 "Not Defined" 64276 "Not Defined" 64275 "Not Defined" 64274 "Not Defined" 64273 "Not Defined" 64272 "Not Defined" 64271 "Not Defined" 64270 "Not Defined" 64269 "Not Defined" 64268 "Not Defined" 64267 "Not Defined" 64266 "Not Defined" 64265 "Not Defined" 64264 "Not Defined" 64263 "Not Defined" 64262 "Not Defined" 64261 "Not Defined" 64260 "Not Defined" 64259 "Not Defined" 64258 "Not Defined" 64257 "Not Defined" 64256 "Not Defined" ;
VAL_ 2680225552 CMO_Output2 65535 "Signal Not Available" 64510 "Not Defined" 64509 "Not Defined" 64508 "Not Defined" 64507 "Not Defined" 64506 "Not Defined" 64505 "Not Defined" 64504 "Not Defined" 64503 "Not Defined" 64502 "Not Defined" 64501 "Not Defined" 64500 "Not Defined" 64499 "Not Defined" 64498 "Not Defined" 64497 "Not Defined" 64496 "Not Defined" 64495 "Not Defined" 64494 "Not Defined" 64493 "Not Defined" 64492 "Not Defined" 64491 "Not Defined" 64490 "Not Defined" 64489 "Not Defined" 64488 "Not Defined" 64487 "Not Defined" 64486 "Not Defined" 64485 "Not Defined" 64484 "Not Defined" 64483 "Not Defined" 64482 "Not Defined" 64481 "Not Defined" 64480 "Not Defined" 64479 "Not Defined" 64478 "Not Defined" 64477 "Not Defined" 64476 "Not Defined" 64475 "Not Defined" 64474 "Not Defined" 64473 "Not Defined" 64472 "Not Defined" 64471 "Not Defined" 64470 "Not Defined" 64469 "Not Defined" 64468 "Not Defined" 64467 "Not Defined" 64466 "Not Defined" 64465 "Not Defined" 64464 "Not Defined" 64463 "Not Defined" 64462 "Not Defined" 64461 "Not Defined" 64460 "Not Defined" 64459 "Not Defined" 64458 "Not Defined" 64457 "Not Defined" 64456 "Not Defined" 64455 "Not Defined" 64454 "Not Defined" 64453 "Not Defined" 64452 "Not Defined" 64451 "Not Defined" 64450 "Not Defined" 64449 "Not Defined" 64448 "Not Defined" 64447 "Not Defined" 64446 "Not Defined" 64445 "Not Defined" 64444 "Not Defined" 64443 "Not Defined" 64442 "Not Defined" 64441 "Not Defined" 64440 "Not Defined" 64439 "Not Defined" 64438 "Not Defined" 64437 "Not Defined" 64436 "Not Defined" 64435 "Not Defined" 64434 "Not Defined" 64433 "Not Defined" 64432 "Not Defined" 64431 "Not Defined" 64430 "Not Defined" 64429 "Not Defined" 64428 "Not Defined" 64427 "Not Defined" 64426 "Not Defined" 64425 "Not Defined" 64424 "Not Defined" 64423 "Not Defined" 64422 "Not Defined" 64421 "Not Defined" 64420 "Not Defined" 64419 "Not Defined" 64418 "Not Defined" 64417 "Not Defined" 64416 "Not Defined" 64415 "Not Defined" 64414 "Not Defined" 64413 "Not Defined" 64412 "Not Defined" 64411 "Not Defined" 64410 "Not Defined" 64409 "Not Defined" 64408 "Not Defined" 64407 "Not Defined" 64406 "Not Defined" 64405 "Not Defined" 64404 "Not Defined" 64403 "Not Defined" 64402 "Not Defined" 64401 "Not Defined" 64400 "Not Defined" 64399 "Not Defined" 64398 "Not Defined" 64397 "Not Defined" 64396 "Not Defined" 64395 "Not Defined" 64394 "Not Defined" 64393 "Not Defined" 64392 "Not Defined" 64391 "Not Defined" 64390 "Not Defined" 64389 "Not Defined" 64388 "Not Defined" 64387 "Not Defined" 64386 "Not Defined" 64385 "Not Defined" 64384 "Not Defined" 64383 "Not Defined" 64382 "Not Defined" 64381 "Not Defined" 64380 "Not Defined" 64379 "Not Defined" 64378 "Not Defined" 64377 "Not Defined" 64376 "Not Defined" 64375 "Not Defined" 64374 "Not Defined" 64373 "Not Defined" 64372 "Not Defined" 64371 "Not Defined" 64370 "Not Defined" 64369 "Not Defined" 64368 "Not Defined" 64367 "Not Defined" 64366 "Not Defined" 64365 "Not Defined" 64364 "Not Defined" 64363 "Not Defined" 64362 "Not Defined" 64361 "Not Defined" 64360 "Not Defined" 64359 "Not Defined" 64358 "Not Defined" 64357 "Not Defined" 64356 "Not Defined" 64355 "Not Defined" 64354 "Not Defined" 64353 "Not Defined" 64352 "Not Defined" 64351 "Not Defined" 64350 "Not Defined" 64349 "Not Defined" 64348 "Not Defined" 64347 "Not Defined" 64346 "Not Defined" 64345 "Not Defined" 64344 "Not Defined" 64343 "Not Defined" 64342 "Not Defined" 64341 "Not Defined" 64340 "Not Defined" 64339 "Not Defined" 64338 "Not Defined" 64337 "Not Defined" 64336 "Not Defined" 64335 "Not Defined" 64334 "Not Defined" 64333 "Not Defined" 64332 "Not Defined" 64331 "Not Defined" 64330 "Not Defined" 64329 "Not Defined" 64328 "Not Defined" 64327 "Not Defined" 64326 "Not Defined" 64325 "Not Defined" 64324 "Not Defined" 64323 "Not Defined" 64322 "Not Defined" 64321 "Not Defined" 64320 "Not Defined" 64319 "Not Defined" 64318 "Not Defined" 64317 "Not Defined" 64316 "Not Defined" 64315 "Not Defined" 64314 "Not Defined" 64313 "Not Defined" 64312 "Not Defined" 64311 "Not Defined" 64310 "Not Defined" 64309 "Not Defined" 64308 "Not Defined" 64307 "Not Defined" 64306 "Not Defined" 64305 "Not Defined" 64304 "Not Defined" 64303 "Not Defined" 64302 "Not Defined" 64301 "Not Defined" 64300 "Not Defined" 64299 "Not Defined" 64298 "Not Defined" 64297 "Not Defined" 64296 "Not Defined" 64295 "Not Defined" 64294 "Not Defined" 64293 "Not Defined" 64292 "Not Defined" 64291 "Not Defined" 64290 "Not Defined" 64289 "Not Defined" 64288 "Not Defined" 64287 "Not Defined" 64286 "Not Defined" 64285 "Not Defined" 64284 "Not Defined" 64283 "Not Defined" 64282 "Not Defined" 64281 "Not Defined" 64280 "Not Defined" 64279 "Not Defined" 64278 "Not Defined" 64277 "Not Defined" 64276 "Not Defined" 64275 "Not Defined" 64274 "Not Defined" 64273 "Not Defined" 64272 "Not Defined" 64271 "Not Defined" 64270 "Not Defined" 64269 "Not Defined" 64268 "Not Defined" 64267 "Not Defined" 64266 "Not Defined" 64265 "Not Defined" 64264 "Not Defined" 64263 "Not Defined" 64262 "Not Defined" 64261 "Not Defined" 64260 "Not Defined" 64259 "Not Defined" 64258 "Not Defined" 64257 "Not Defined" 64256 "Not Defined" ;
VAL_ 2680225552 CMO_Output1 65535 "Signal Not Available" 64510 "Not Defined" 64509 "Not Defined" 64508 "Not Defined" 64507 "Not Defined" 64506 "Not Defined" 64505 "Not Defined" 64504 "Not Defined" 64503 "Not Defined" 64502 "Not Defined" 64501 "Not Defined" 64500 "Not Defined" 64499 "Not Defined" 64498 "Not Defined" 64497 "Not Defined" 64496 "Not Defined" 64495 "Not Defined" 64494 "Not Defined" 64493 "Not Defined" 64492 "Not Defined" 64491 "Not Defined" 64490 "Not Defined" 64489 "Not Defined" 64488 "Not Defined" 64487 "Not Defined" 64486 "Not Defined" 64485 "Not Defined" 64484 "Not Defined" 64483 "Not Defined" 64482 "Not Defined" 64481 "Not Defined" 64480 "Not Defined" 64479 "Not Defined" 64478 "Not Defined" 64477 "Not Defined" 64476 "Not Defined" 64475 "Not Defined" 64474 "Not Defined" 64473 "Not Defined" 64472 "Not Defined" 64471 "Not Defined" 64470 "Not Defined" 64469 "Not Defined" 64468 "Not Defined" 64467 "Not Defined" 64466 "Not Defined" 64465 "Not Defined" 64464 "Not Defined" 64463 "Not Defined" 64462 "Not Defined" 64461 "Not Defined" 64460 "Not Defined" 64459 "Not Defined" 64458 "Not Defined" 64457 "Not Defined" 64456 "Not Defined" 64455 "Not Defined" 64454 "Not Defined" 64453 "Not Defined" 64452 "Not Defined" 64451 "Not Defined" 64450 "Not Defined" 64449 "Not Defined" 64448 "Not Defined" 64447 "Not Defined" 64446 "Not Defined" 64445 "Not Defined" 64444 "Not Defined" 64443 "Not Defined" 64442 "Not Defined" 64441 "Not Defined" 64440 "Not Defined" 64439 "Not Defined" 64438 "Not Defined" 64437 "Not Defined" 64436 "Not Defined" 64435 "Not Defined" 64434 "Not Defined" 64433 "Not Defined" 64432 "Not Defined" 64431 "Not Defined" 64430 "Not Defined" 64429 "Not Defined" 64428 "Not Defined" 64427 "Not Defined" 64426 "Not Defined" 64425 "Not Defined" 64424 "Not Defined" 64423 "Not Defined" 64422 "Not Defined" 64421 "Not Defined" 64420 "Not Defined" 64419 "Not Defined" 64418 "Not Defined" 64417 "Not Defined" 64416 "Not Defined" 64415 "Not Defined" 64414 "Not Defined" 64413 "Not Defined" 64412 "Not Defined" 64411 "Not Defined" 64410 "Not Defined" 64409 "Not Defined" 64408 "Not Defined" 64407 "Not Defined" 64406 "Not Defined" 64405 "Not Defined" 64404 "Not Defined" 64403 "Not Defined" 64402 "Not Defined" 64401 "Not Defined" 64400 "Not Defined" 64399 "Not Defined" 64398 "Not Defined" 64397 "Not Defined" 64396 "Not Defined" 64395 "Not Defined" 64394 "Not Defined" 64393 "Not Defined" 64392 "Not Defined" 64391 "Not Defined" 64390 "Not Defined" 64389 "Not Defined" 64388 "Not Defined" 64387 "Not Defined" 64386 "Not Defined" 64385 "Not Defined" 64384 "Not Defined" 64383 "Not Defined" 64382 "Not Defined" 64381 "Not Defined" 64380 "Not Defined" 64379 "Not Defined" 64378 "Not Defined" 64377 "Not Defined" 64376 "Not Defined" 64375 "Not Defined" 64374 "Not Defined" 64373 "Not Defined" 64372 "Not Defined" 64371 "Not Defined" 64370 "Not Defined" 64369 "Not Defined" 64368 "Not Defined" 64367 "Not Defined" 64366 "Not Defined" 64365 "Not Defined" 64364 "Not Defined" 64363 "Not Defined" 64362 "Not Defined" 64361 "Not Defined" 64360 "Not Defined" 64359 "Not Defined" 64358 "Not Defined" 64357 "Not Defined" 64356 "Not Defined" 64355 "Not Defined" 64354 "Not Defined" 64353 "Not Defined" 64352 "Not Defined" 64351 "Not Defined" 64350 "Not Defined" 64349 "Not Defined" 64348 "Not Defined" 64347 "Not Defined" 64346 "Not Defined" 64345 "Not Defined" 64344 "Not Defined" 64343 "Not Defined" 64342 "Not Defined" 64341 "Not Defined" 64340 "Not Defined" 64339 "Not Defined" 64338 "Not Defined" 64337 "Not Defined" 64336 "Not Defined" 64335 "Not Defined" 64334 "Not Defined" 64333 "Not Defined" 64332 "Not Defined" 64331 "Not Defined" 64330 "Not Defined" 64329 "Not Defined" 64328 "Not Defined" 64327 "Not Defined" 64326 "Not Defined" 64325 "Not Defined" 64324 "Not Defined" 64323 "Not Defined" 64322 "Not Defined" 64321 "Not Defined" 64320 "Not Defined" 64319 "Not Defined" 64318 "Not Defined" 64317 "Not Defined" 64316 "Not Defined" 64315 "Not Defined" 64314 "Not Defined" 64313 "Not Defined" 64312 "Not Defined" 64311 "Not Defined" 64310 "Not Defined" 64309 "Not Defined" 64308 "Not Defined" 64307 "Not Defined" 64306 "Not Defined" 64305 "Not Defined" 64304 "Not Defined" 64303 "Not Defined" 64302 "Not Defined" 64301 "Not Defined" 64300 "Not Defined" 64299 "Not Defined" 64298 "Not Defined" 64297 "Not Defined" 64296 "Not Defined" 64295 "Not Defined" 64294 "Not Defined" 64293 "Not Defined" 64292 "Not Defined" 64291 "Not Defined" 64290 "Not Defined" 64289 "Not Defined" 64288 "Not Defined" 64287 "Not Defined" 64286 "Not Defined" 64285 "Not Defined" 64284 "Not Defined" 64283 "Not Defined" 64282 "Not Defined" 64281 "Not Defined" 64280 "Not Defined" 64279 "Not Defined" 64278 "Not Defined" 64277 "Not Defined" 64276 "Not Defined" 64275 "Not Defined" 64274 "Not Defined" 64273 "Not Defined" 64272 "Not Defined" 64271 "Not Defined" 64270 "Not Defined" 64269 "Not Defined" 64268 "Not Defined" 64267 "Not Defined" 64266 "Not Defined" 64265 "Not Defined" 64264 "Not Defined" 64263 "Not Defined" 64262 "Not Defined" 64261 "Not Defined" 64260 "Not Defined" 64259 "Not Defined" 64258 "Not Defined" 64257 "Not Defined" 64256 "Not Defined" ;
VAL_ 2680225668 ETSD2_PyPressure 65024 "Sensor Elektric Alarm" 64768 "Sensor Not Calibrated" ;
VAL_ 2680225668 ETSD2_PxPressure 65024 "Sensor Elektric Alarm" 64768 "Sensor Not Calibrated" ;
VAL_ 2680225668 ETSD2_Rear2Angle 65535 "Signal not available" 64510 "Not Defined" 64509 "Not Defined" 64508 "Not Defined" 64507 "Not Defined" 64506 "Not Defined" 64505 "Not Defined" 64504 "Not Defined" 64503 "Not Defined" 64502 "Not Defined" 64501 "Not Defined" 64500 "Not Defined" 64499 "Not Defined" 64498 "Not Defined" 64497 "Not Defined" 64496 "Not Defined" 64495 "Not Defined" 64494 "Not Defined" 64493 "Not Defined" 64492 "Not Defined" 64491 "Not Defined" 64490 "Not Defined" 64489 "Not Defined" 64488 "Not Defined" 64487 "Not Defined" 64486 "Not Defined" 64485 "Not Defined" 64484 "Not Defined" 64483 "Not Defined" 64482 "Not Defined" 64481 "Not Defined" 64480 "Not Defined" 64479 "Not Defined" 64478 "Not Defined" 64477 "Not Defined" 64476 "Not Defined" 64475 "Not Defined" 64474 "Not Defined" 64473 "Not Defined" 64472 "Not Defined" 64471 "Not Defined" 64470 "Not Defined" 64469 "Not Defined" 64468 "Not Defined" 64467 "Not Defined" 64466 "Not Defined" 64465 "Not Defined" 64464 "Not Defined" 64463 "Not Defined" 64462 "Not Defined" 64461 "Not Defined" 64460 "Not Defined" 64459 "Not Defined" 64458 "Not Defined" 64457 "Not Defined" 64456 "Not Defined" 64455 "Not Defined" 64454 "Not Defined" 64453 "Not Defined" 64452 "Not Defined" 64451 "Not Defined" 64450 "Not Defined" 64449 "Not Defined" 64448 "Not Defined" 64447 "Not Defined" 64446 "Not Defined" 64445 "Not Defined" 64444 "Not Defined" 64443 "Not Defined" 64442 "Not Defined" 64441 "Not Defined" 64440 "Not Defined" 64439 "Not Defined" 64438 "Not Defined" 64437 "Not Defined" 64436 "Not Defined" 64435 "Not Defined" 64434 "Not Defined" 64433 "Not Defined" 64432 "Not Defined" 64431 "Not Defined" 64430 "Not Defined" 64429 "Not Defined" 64428 "Not Defined" 64427 "Not Defined" 64426 "Not Defined" 64425 "Not Defined" 64424 "Not Defined" 64423 "Not Defined" 64422 "Not Defined" 64421 "Not Defined" 64420 "Not Defined" 64419 "Not Defined" 64418 "Not Defined" 64417 "Not Defined" 64416 "Not Defined" 64415 "Not Defined" 64414 "Not Defined" 64413 "Not Defined" 64412 "Not Defined" 64411 "Not Defined" 64410 "Not Defined" 64409 "Not Defined" 64408 "Not Defined" 64407 "Not Defined" 64406 "Not Defined" 64405 "Not Defined" 64404 "Not Defined" 64403 "Not Defined" 64402 "Not Defined" 64401 "Not Defined" 64400 "Not Defined" 64399 "Not Defined" 64398 "Not Defined" 64397 "Not Defined" 64396 "Not Defined" 64395 "Not Defined" 64394 "Not Defined" 64393 "Not Defined" 64392 "Not Defined" 64391 "Not Defined" 64390 "Not Defined" 64389 "Not Defined" 64388 "Not Defined" 64387 "Not Defined" 64386 "Not Defined" 64385 "Not Defined" 64384 "Not Defined" 64383 "Not Defined" 64382 "Not Defined" 64381 "Not Defined" 64380 "Not Defined" 64379 "Not Defined" 64378 "Not Defined" 64377 "Not Defined" 64376 "Not Defined" 64375 "Not Defined" 64374 "Not Defined" 64373 "Not Defined" 64372 "Not Defined" 64371 "Not Defined" 64370 "Not Defined" 64369 "Not Defined" 64368 "Not Defined" 64367 "Not Defined" 64366 "Not Defined" 64365 "Not Defined" 64364 "Not Defined" 64363 "Not Defined" 64362 "Not Defined" 64361 "Not Defined" 64360 "Not Defined" 64359 "Not Defined" 64358 "Not Defined" 64357 "Not Defined" 64356 "Not Defined" 64355 "Not Defined" 64354 "Not Defined" 64353 "Not Defined" 64352 "Not Defined" 64351 "Not Defined" 64350 "Not Defined" 64349 "Not Defined" 64348 "Not Defined" 64347 "Not Defined" 64346 "Not Defined" 64345 "Not Defined" 64344 "Not Defined" 64343 "Not Defined" 64342 "Not Defined" 64341 "Not Defined" 64340 "Not Defined" 64339 "Not Defined" 64338 "Not Defined" 64337 "Not Defined" 64336 "Not Defined" 64335 "Not Defined" 64334 "Not Defined" 64333 "Not Defined" 64332 "Not Defined" 64331 "Not Defined" 64330 "Not Defined" 64329 "Not Defined" 64328 "Not Defined" 64327 "Not Defined" 64326 "Not Defined" 64325 "Not Defined" 64324 "Not Defined" 64323 "Not Defined" 64322 "Not Defined" 64321 "Not Defined" 64320 "Not Defined" 64319 "Not Defined" 64318 "Not Defined" 64317 "Not Defined" 64316 "Not Defined" 64315 "Not Defined" 64314 "Not Defined" 64313 "Not Defined" 64312 "Not Defined" 64311 "Not Defined" 64310 "Not Defined" 64309 "Not Defined" 64308 "Not Defined" 64307 "Not Defined" 64306 "Not Defined" 64305 "Not Defined" 64304 "Not Defined" 64303 "Not Defined" 64302 "Not Defined" 64301 "Not Defined" 64300 "Not Defined" 64299 "Not Defined" 64298 "Not Defined" 64297 "Not Defined" 64296 "Not Defined" 64295 "Not Defined" 64294 "Not Defined" 64293 "Not Defined" 64292 "Not Defined" 64291 "Not Defined" 64290 "Not Defined" 64289 "Not Defined" 64288 "Not Defined" 64287 "Not Defined" 64286 "Not Defined" 64285 "Not Defined" 64284 "Not Defined" 64283 "Not Defined" 64282 "Not Defined" 64281 "Not Defined" 64280 "Not Defined" 64279 "Not Defined" 64278 "Not Defined" 64277 "Not Defined" 64276 "Not Defined" 64275 "Not Defined" 64274 "Not Defined" 64273 "Not Defined" 64272 "Not Defined" 64271 "Not Defined" 64270 "Not Defined" 64269 "Not Defined" 64268 "Not Defined" 64267 "Not Defined" 64266 "Not Defined" 64265 "Not Defined" 64264 "Not Defined" 64263 "Not Defined" 64262 "Not Defined" 64261 "Not Defined" 64260 "Not Defined" 64259 "Not Defined" 64258 "Not Defined" 64257 "Not Defined" 64256 "Not Defined" ;
VAL_ 2680225668 ETSD2_Target2Angle 65535 "Signal not available" 64510 "Not Defined" 64509 "Not Defined" 64508 "Not Defined" 64507 "Not Defined" 64506 "Not Defined" 64505 "Not Defined" 64504 "Not Defined" 64503 "Not Defined" 64502 "Not Defined" 64501 "Not Defined" 64500 "Not Defined" 64499 "Not Defined" 64498 "Not Defined" 64497 "Not Defined" 64496 "Not Defined" 64495 "Not Defined" 64494 "Not Defined" 64493 "Not Defined" 64492 "Not Defined" 64491 "Not Defined" 64490 "Not Defined" 64489 "Not Defined" 64488 "Not Defined" 64487 "Not Defined" 64486 "Not Defined" 64485 "Not Defined" 64484 "Not Defined" 64483 "Not Defined" 64482 "Not Defined" 64481 "Not Defined" 64480 "Not Defined" 64479 "Not Defined" 64478 "Not Defined" 64477 "Not Defined" 64476 "Not Defined" 64475 "Not Defined" 64474 "Not Defined" 64473 "Not Defined" 64472 "Not Defined" 64471 "Not Defined" 64470 "Not Defined" 64469 "Not Defined" 64468 "Not Defined" 64467 "Not Defined" 64466 "Not Defined" 64465 "Not Defined" 64464 "Not Defined" 64463 "Not Defined" 64462 "Not Defined" 64461 "Not Defined" 64460 "Not Defined" 64459 "Not Defined" 64458 "Not Defined" 64457 "Not Defined" 64456 "Not Defined" 64455 "Not Defined" 64454 "Not Defined" 64453 "Not Defined" 64452 "Not Defined" 64451 "Not Defined" 64450 "Not Defined" 64449 "Not Defined" 64448 "Not Defined" 64447 "Not Defined" 64446 "Not Defined" 64445 "Not Defined" 64444 "Not Defined" 64443 "Not Defined" 64442 "Not Defined" 64441 "Not Defined" 64440 "Not Defined" 64439 "Not Defined" 64438 "Not Defined" 64437 "Not Defined" 64436 "Not Defined" 64435 "Not Defined" 64434 "Not Defined" 64433 "Not Defined" 64432 "Not Defined" 64431 "Not Defined" 64430 "Not Defined" 64429 "Not Defined" 64428 "Not Defined" 64427 "Not Defined" 64426 "Not Defined" 64425 "Not Defined" 64424 "Not Defined" 64423 "Not Defined" 64422 "Not Defined" 64421 "Not Defined" 64420 "Not Defined" 64419 "Not Defined" 64418 "Not Defined" 64417 "Not Defined" 64416 "Not Defined" 64415 "Not Defined" 64414 "Not Defined" 64413 "Not Defined" 64412 "Not Defined" 64411 "Not Defined" 64410 "Not Defined" 64409 "Not Defined" 64408 "Not Defined" 64407 "Not Defined" 64406 "Not Defined" 64405 "Not Defined" 64404 "Not Defined" 64403 "Not Defined" 64402 "Not Defined" 64401 "Not Defined" 64400 "Not Defined" 64399 "Not Defined" 64398 "Not Defined" 64397 "Not Defined" 64396 "Not Defined" 64395 "Not Defined" 64394 "Not Defined" 64393 "Not Defined" 64392 "Not Defined" 64391 "Not Defined" 64390 "Not Defined" 64389 "Not Defined" 64388 "Not Defined" 64387 "Not Defined" 64386 "Not Defined" 64385 "Not Defined" 64384 "Not Defined" 64383 "Not Defined" 64382 "Not Defined" 64381 "Not Defined" 64380 "Not Defined" 64379 "Not Defined" 64378 "Not Defined" 64377 "Not Defined" 64376 "Not Defined" 64375 "Not Defined" 64374 "Not Defined" 64373 "Not Defined" 64372 "Not Defined" 64371 "Not Defined" 64370 "Not Defined" 64369 "Not Defined" 64368 "Not Defined" 64367 "Not Defined" 64366 "Not Defined" 64365 "Not Defined" 64364 "Not Defined" 64363 "Not Defined" 64362 "Not Defined" 64361 "Not Defined" 64360 "Not Defined" 64359 "Not Defined" 64358 "Not Defined" 64357 "Not Defined" 64356 "Not Defined" 64355 "Not Defined" 64354 "Not Defined" 64353 "Not Defined" 64352 "Not Defined" 64351 "Not Defined" 64350 "Not Defined" 64349 "Not Defined" 64348 "Not Defined" 64347 "Not Defined" 64346 "Not Defined" 64345 "Not Defined" 64344 "Not Defined" 64343 "Not Defined" 64342 "Not Defined" 64341 "Not Defined" 64340 "Not Defined" 64339 "Not Defined" 64338 "Not Defined" 64337 "Not Defined" 64336 "Not Defined" 64335 "Not Defined" 64334 "Not Defined" 64333 "Not Defined" 64332 "Not Defined" 64331 "Not Defined" 64330 "Not Defined" 64329 "Not Defined" 64328 "Not Defined" 64327 "Not Defined" 64326 "Not Defined" 64325 "Not Defined" 64324 "Not Defined" 64323 "Not Defined" 64322 "Not Defined" 64321 "Not Defined" 64320 "Not Defined" 64319 "Not Defined" 64318 "Not Defined" 64317 "Not Defined" 64316 "Not Defined" 64315 "Not Defined" 64314 "Not Defined" 64313 "Not Defined" 64312 "Not Defined" 64311 "Not Defined" 64310 "Not Defined" 64309 "Not Defined" 64308 "Not Defined" 64307 "Not Defined" 64306 "Not Defined" 64305 "Not Defined" 64304 "Not Defined" 64303 "Not Defined" 64302 "Not Defined" 64301 "Not Defined" 64300 "Not Defined" 64299 "Not Defined" 64298 "Not Defined" 64297 "Not Defined" 64296 "Not Defined" 64295 "Not Defined" 64294 "Not Defined" 64293 "Not Defined" 64292 "Not Defined" 64291 "Not Defined" 64290 "Not Defined" 64289 "Not Defined" 64288 "Not Defined" 64287 "Not Defined" 64286 "Not Defined" 64285 "Not Defined" 64284 "Not Defined" 64283 "Not Defined" 64282 "Not Defined" 64281 "Not Defined" 64280 "Not Defined" 64279 "Not Defined" 64278 "Not Defined" 64277 "Not Defined" 64276 "Not Defined" 64275 "Not Defined" 64274 "Not Defined" 64273 "Not Defined" 64272 "Not Defined" 64271 "Not Defined" 64270 "Not Defined" 64269 "Not Defined" 64268 "Not Defined" 64267 "Not Defined" 64266 "Not Defined" 64265 "Not Defined" 64264 "Not Defined" 64263 "Not Defined" 64262 "Not Defined" 64261 "Not Defined" 64260 "Not Defined" 64259 "Not Defined" 64258 "Not Defined" 64257 "Not Defined" 64256 "Not Defined" ;
VAL_ 2680225665 ETSD1_InSpeed2 238 "C3 Speed too loew for validation" 255 "Speed Not Available" 254 "Knorr Kline no data for 80 ms" 253 "Knorr Kline no data in frame" 252 "Knorr Kline Framing Error" 251 "Knorr Kline Cs Error" 250 "Knorr Kline no header for 80ms" 249 "Speed Above 150 km/h" 248 "GPS No message(s) received" 247 "GPS No Fix" 246 "Can Signal not present" 245 "Can Signal not plausible" 244 "Wabco Pulse not present" 243 "Wabco Pulsetime below 150 ms" 242 "C3 Speed Deceleration rate too h" 241 "C3 Speed Kfactor out of range" 240 "C3 Speed Kfactor not stable" 239 "C3 Speed Kfactor not saved in ee" ;
VAL_ 2680225665 ETSD1_InSpeed1 238 "C3 Speed too loew for validation" 255 "Speed Not Available" 254 "Knorr Kline no data for 80 ms" 253 "Knorr Kline no data in frame" 252 "Knorr Kline Framing Error" 251 "Knorr Kline Cs Error" 250 "Knorr Kline no header for 80ms" 249 "Speed Above 150 km/h" 248 "GPS No message(s) received" 247 "GPS No Fix" 246 "Can Signal not present" 245 "Can Signal not plausible" 244 "Wabco Pulse not present" 243 "Wabco Pulsetime below 150 ms" 242 "C3 Speed Deceleration rate too h" 241 "C3 Speed Kfactor out of range" 240 "C3 Speed Kfactor not stable" 239 "C3 Speed Kfactor not saved in ee" ;
VAL_ 2680225665 ETSD1_RearAngle 65535 "Signal not available" 64510 "Not Defined" 64509 "Not Defined" 64508 "Not Defined" 64507 "Not Defined" 64506 "Not Defined" 64505 "Not Defined" 64504 "Not Defined" 64503 "Not Defined" 64502 "Not Defined" 64501 "Not Defined" 64500 "Not Defined" 64499 "Not Defined" 64498 "Not Defined" 64497 "Not Defined" 64496 "Not Defined" 64495 "Not Defined" 64494 "Not Defined" 64493 "Not Defined" 64492 "Not Defined" 64491 "Not Defined" 64490 "Not Defined" 64489 "Not Defined" 64488 "Not Defined" 64487 "Not Defined" 64486 "Not Defined" 64485 "Not Defined" 64484 "Not Defined" 64483 "Not Defined" 64482 "Not Defined" 64481 "Not Defined" 64480 "Not Defined" 64479 "Not Defined" 64478 "Not Defined" 64477 "Not Defined" 64476 "Not Defined" 64475 "Not Defined" 64474 "Not Defined" 64473 "Not Defined" 64472 "Not Defined" 64471 "Not Defined" 64470 "Not Defined" 64469 "Not Defined" 64468 "Not Defined" 64467 "Not Defined" 64466 "Not Defined" 64465 "Not Defined" 64464 "Not Defined" 64463 "Not Defined" 64462 "Not Defined" 64461 "Not Defined" 64460 "Not Defined" 64459 "Not Defined" 64458 "Not Defined" 64457 "Not Defined" 64456 "Not Defined" 64455 "Not Defined" 64454 "Not Defined" 64453 "Not Defined" 64452 "Not Defined" 64451 "Not Defined" 64450 "Not Defined" 64449 "Not Defined" 64448 "Not Defined" 64447 "Not Defined" 64446 "Not Defined" 64445 "Not Defined" 64444 "Not Defined" 64443 "Not Defined" 64442 "Not Defined" 64441 "Not Defined" 64440 "Not Defined" 64439 "Not Defined" 64438 "Not Defined" 64437 "Not Defined" 64436 "Not Defined" 64435 "Not Defined" 64434 "Not Defined" 64433 "Not Defined" 64432 "Not Defined" 64431 "Not Defined" 64430 "Not Defined" 64429 "Not Defined" 64428 "Not Defined" 64427 "Not Defined" 64426 "Not Defined" 64425 "Not Defined" 64424 "Not Defined" 64423 "Not Defined" 64422 "Not Defined" 64421 "Not Defined" 64420 "Not Defined" 64419 "Not Defined" 64418 "Not Defined" 64417 "Not Defined" 64416 "Not Defined" 64415 "Not Defined" 64414 "Not Defined" 64413 "Not Defined" 64412 "Not Defined" 64411 "Not Defined" 64410 "Not Defined" 64409 "Not Defined" 64408 "Not Defined" 64407 "Not Defined" 64406 "Not Defined" 64405 "Not Defined" 64404 "Not Defined" 64403 "Not Defined" 64402 "Not Defined" 64401 "Not Defined" 64400 "Not Defined" 64399 "Not Defined" 64398 "Not Defined" 64397 "Not Defined" 64396 "Not Defined" 64395 "Not Defined" 64394 "Not Defined" 64393 "Not Defined" 64392 "Not Defined" 64391 "Not Defined" 64390 "Not Defined" 64389 "Not Defined" 64388 "Not Defined" 64387 "Not Defined" 64386 "Not Defined" 64385 "Not Defined" 64384 "Not Defined" 64383 "Not Defined" 64382 "Not Defined" 64381 "Not Defined" 64380 "Not Defined" 64379 "Not Defined" 64378 "Not Defined" 64377 "Not Defined" 64376 "Not Defined" 64375 "Not Defined" 64374 "Not Defined" 64373 "Not Defined" 64372 "Not Defined" 64371 "Not Defined" 64370 "Not Defined" 64369 "Not Defined" 64368 "Not Defined" 64367 "Not Defined" 64366 "Not Defined" 64365 "Not Defined" 64364 "Not Defined" 64363 "Not Defined" 64362 "Not Defined" 64361 "Not Defined" 64360 "Not Defined" 64359 "Not Defined" 64358 "Not Defined" 64357 "Not Defined" 64356 "Not Defined" 64355 "Not Defined" 64354 "Not Defined" 64353 "Not Defined" 64352 "Not Defined" 64351 "Not Defined" 64350 "Not Defined" 64349 "Not Defined" 64348 "Not Defined" 64347 "Not Defined" 64346 "Not Defined" 64345 "Not Defined" 64344 "Not Defined" 64343 "Not Defined" 64342 "Not Defined" 64341 "Not Defined" 64340 "Not Defined" 64339 "Not Defined" 64338 "Not Defined" 64337 "Not Defined" 64336 "Not Defined" 64335 "Not Defined" 64334 "Not Defined" 64333 "Not Defined" 64332 "Not Defined" 64331 "Not Defined" 64330 "Not Defined" 64329 "Not Defined" 64328 "Not Defined" 64327 "Not Defined" 64326 "Not Defined" 64325 "Not Defined" 64324 "Not Defined" 64323 "Not Defined" 64322 "Not Defined" 64321 "Not Defined" 64320 "Not Defined" 64319 "Not Defined" 64318 "Not Defined" 64317 "Not Defined" 64316 "Not Defined" 64315 "Not Defined" 64314 "Not Defined" 64313 "Not Defined" 64312 "Not Defined" 64311 "Not Defined" 64310 "Not Defined" 64309 "Not Defined" 64308 "Not Defined" 64307 "Not Defined" 64306 "Not Defined" 64305 "Not Defined" 64304 "Not Defined" 64303 "Not Defined" 64302 "Not Defined" 64301 "Not Defined" 64300 "Not Defined" 64299 "Not Defined" 64298 "Not Defined" 64297 "Not Defined" 64296 "Not Defined" 64295 "Not Defined" 64294 "Not Defined" 64293 "Not Defined" 64292 "Not Defined" 64291 "Not Defined" 64290 "Not Defined" 64289 "Not Defined" 64288 "Not Defined" 64287 "Not Defined" 64286 "Not Defined" 64285 "Not Defined" 64284 "Not Defined" 64283 "Not Defined" 64282 "Not Defined" 64281 "Not Defined" 64280 "Not Defined" 64279 "Not Defined" 64278 "Not Defined" 64277 "Not Defined" 64276 "Not Defined" 64275 "Not Defined" 64274 "Not Defined" 64273 "Not Defined" 64272 "Not Defined" 64271 "Not Defined" 64270 "Not Defined" 64269 "Not Defined" 64268 "Not Defined" 64267 "Not Defined" 64266 "Not Defined" 64265 "Not Defined" 64264 "Not Defined" 64263 "Not Defined" 64262 "Not Defined" 64261 "Not Defined" 64260 "Not Defined" 64259 "Not Defined" 64258 "Not Defined" 64257 "Not Defined" 64256 "Not Defined" ;
VAL_ 2680225665 ETSD1_FrontAngle 65535 "Signal not available" 64510 "Not Defined" 64509 "Not Defined" 64508 "Not Defined" 64507 "Not Defined" 64506 "Not Defined" 64505 "Not Defined" 64504 "Not Defined" 64503 "Not Defined" 64502 "Not Defined" 64501 "Not Defined" 64500 "Not Defined" 64499 "Not Defined" 64498 "Not Defined" 64497 "Not Defined" 64496 "Not Defined" 64495 "Not Defined" 64494 "Not Defined" 64493 "Not Defined" 64492 "Not Defined" 64491 "Not Defined" 64490 "Not Defined" 64489 "Not Defined" 64488 "Not Defined" 64487 "Not Defined" 64486 "Not Defined" 64485 "Not Defined" 64484 "Not Defined" 64483 "Not Defined" 64482 "Not Defined" 64481 "Not Defined" 64480 "Not Defined" 64479 "Not Defined" 64478 "Not Defined" 64477 "Not Defined" 64476 "Not Defined" 64475 "Not Defined" 64474 "Not Defined" 64473 "Not Defined" 64472 "Not Defined" 64471 "Not Defined" 64470 "Not Defined" 64469 "Not Defined" 64468 "Not Defined" 64467 "Not Defined" 64466 "Not Defined" 64465 "Not Defined" 64464 "Not Defined" 64463 "Not Defined" 64462 "Not Defined" 64461 "Not Defined" 64460 "Not Defined" 64459 "Not Defined" 64458 "Not Defined" 64457 "Not Defined" 64456 "Not Defined" 64455 "Not Defined" 64454 "Not Defined" 64453 "Not Defined" 64452 "Not Defined" 64451 "Not Defined" 64450 "Not Defined" 64449 "Not Defined" 64448 "Not Defined" 64447 "Not Defined" 64446 "Not Defined" 64445 "Not Defined" 64444 "Not Defined" 64443 "Not Defined" 64442 "Not Defined" 64441 "Not Defined" 64440 "Not Defined" 64439 "Not Defined" 64438 "Not Defined" 64437 "Not Defined" 64436 "Not Defined" 64435 "Not Defined" 64434 "Not Defined" 64433 "Not Defined" 64432 "Not Defined" 64431 "Not Defined" 64430 "Not Defined" 64429 "Not Defined" 64428 "Not Defined" 64427 "Not Defined" 64426 "Not Defined" 64425 "Not Defined" 64424 "Not Defined" 64423 "Not Defined" 64422 "Not Defined" 64421 "Not Defined" 64420 "Not Defined" 64419 "Not Defined" 64418 "Not Defined" 64417 "Not Defined" 64416 "Not Defined" 64415 "Not Defined" 64414 "Not Defined" 64413 "Not Defined" 64412 "Not Defined" 64411 "Not Defined" 64410 "Not Defined" 64409 "Not Defined" 64408 "Not Defined" 64407 "Not Defined" 64406 "Not Defined" 64405 "Not Defined" 64404 "Not Defined" 64403 "Not Defined" 64402 "Not Defined" 64401 "Not Defined" 64400 "Not Defined" 64399 "Not Defined" 64398 "Not Defined" 64397 "Not Defined" 64396 "Not Defined" 64395 "Not Defined" 64394 "Not Defined" 64393 "Not Defined" 64392 "Not Defined" 64391 "Not Defined" 64390 "Not Defined" 64389 "Not Defined" 64388 "Not Defined" 64387 "Not Defined" 64386 "Not Defined" 64385 "Not Defined" 64384 "Not Defined" 64383 "Not Defined" 64382 "Not Defined" 64381 "Not Defined" 64380 "Not Defined" 64379 "Not Defined" 64378 "Not Defined" 64377 "Not Defined" 64376 "Not Defined" 64375 "Not Defined" 64374 "Not Defined" 64373 "Not Defined" 64372 "Not Defined" 64371 "Not Defined" 64370 "Not Defined" 64369 "Not Defined" 64368 "Not Defined" 64367 "Not Defined" 64366 "Not Defined" 64365 "Not Defined" 64364 "Not Defined" 64363 "Not Defined" 64362 "Not Defined" 64361 "Not Defined" 64360 "Not Defined" 64359 "Not Defined" 64358 "Not Defined" 64357 "Not Defined" 64356 "Not Defined" 64355 "Not Defined" 64354 "Not Defined" 64353 "Not Defined" 64352 "Not Defined" 64351 "Not Defined" 64350 "Not Defined" 64349 "Not Defined" 64348 "Not Defined" 64347 "Not Defined" 64346 "Not Defined" 64345 "Not Defined" 64344 "Not Defined" 64343 "Not Defined" 64342 "Not Defined" 64341 "Not Defined" 64340 "Not Defined" 64339 "Not Defined" 64338 "Not Defined" 64337 "Not Defined" 64336 "Not Defined" 64335 "Not Defined" 64334 "Not Defined" 64333 "Not Defined" 64332 "Not Defined" 64331 "Not Defined" 64330 "Not Defined" 64329 "Not Defined" 64328 "Not Defined" 64327 "Not Defined" 64326 "Not Defined" 64325 "Not Defined" 64324 "Not Defined" 64323 "Not Defined" 64322 "Not Defined" 64321 "Not Defined" 64320 "Not Defined" 64319 "Not Defined" 64318 "Not Defined" 64317 "Not Defined" 64316 "Not Defined" 64315 "Not Defined" 64314 "Not Defined" 64313 "Not Defined" 64312 "Not Defined" 64311 "Not Defined" 64310 "Not Defined" 64309 "Not Defined" 64308 "Not Defined" 64307 "Not Defined" 64306 "Not Defined" 64305 "Not Defined" 64304 "Not Defined" 64303 "Not Defined" 64302 "Not Defined" 64301 "Not Defined" 64300 "Not Defined" 64299 "Not Defined" 64298 "Not Defined" 64297 "Not Defined" 64296 "Not Defined" 64295 "Not Defined" 64294 "Not Defined" 64293 "Not Defined" 64292 "Not Defined" 64291 "Not Defined" 64290 "Not Defined" 64289 "Not Defined" 64288 "Not Defined" 64287 "Not Defined" 64286 "Not Defined" 64285 "Not Defined" 64284 "Not Defined" 64283 "Not Defined" 64282 "Not Defined" 64281 "Not Defined" 64280 "Not Defined" 64279 "Not Defined" 64278 "Not Defined" 64277 "Not Defined" 64276 "Not Defined" 64275 "Not Defined" 64274 "Not Defined" 64273 "Not Defined" 64272 "Not Defined" 64271 "Not Defined" 64270 "Not Defined" 64269 "Not Defined" 64268 "Not Defined" 64267 "Not Defined" 64266 "Not Defined" 64265 "Not Defined" 64264 "Not Defined" 64263 "Not Defined" 64262 "Not Defined" 64261 "Not Defined" 64260 "Not Defined" 64259 "Not Defined" 64258 "Not Defined" 64257 "Not Defined" 64256 "Not Defined" ;
VAL_ 2680225665 ETSD1_TargetAngle 65535 "Signal not available" 64510 "Not Defined" 64509 "Not Defined" 64508 "Not Defined" 64507 "Not Defined" 64506 "Not Defined" 64505 "Not Defined" 64504 "Not Defined" 64503 "Not Defined" 64502 "Not Defined" 64501 "Not Defined" 64500 "Not Defined" 64499 "Not Defined" 64498 "Not Defined" 64497 "Not Defined" 64496 "Not Defined" 64495 "Not Defined" 64494 "Not Defined" 64493 "Not Defined" 64492 "Not Defined" 64491 "Not Defined" 64490 "Not Defined" 64489 "Not Defined" 64488 "Not Defined" 64487 "Not Defined" 64486 "Not Defined" 64485 "Not Defined" 64484 "Not Defined" 64483 "Not Defined" 64482 "Not Defined" 64481 "Not Defined" 64480 "Not Defined" 64479 "Not Defined" 64478 "Not Defined" 64477 "Not Defined" 64476 "Not Defined" 64475 "Not Defined" 64474 "Not Defined" 64473 "Not Defined" 64472 "Not Defined" 64471 "Not Defined" 64470 "Not Defined" 64469 "Not Defined" 64468 "Not Defined" 64467 "Not Defined" 64466 "Not Defined" 64465 "Not Defined" 64464 "Not Defined" 64463 "Not Defined" 64462 "Not Defined" 64461 "Not Defined" 64460 "Not Defined" 64459 "Not Defined" 64458 "Not Defined" 64457 "Not Defined" 64456 "Not Defined" 64455 "Not Defined" 64454 "Not Defined" 64453 "Not Defined" 64452 "Not Defined" 64451 "Not Defined" 64450 "Not Defined" 64449 "Not Defined" 64448 "Not Defined" 64447 "Not Defined" 64446 "Not Defined" 64445 "Not Defined" 64444 "Not Defined" 64443 "Not Defined" 64442 "Not Defined" 64441 "Not Defined" 64440 "Not Defined" 64439 "Not Defined" 64438 "Not Defined" 64437 "Not Defined" 64436 "Not Defined" 64435 "Not Defined" 64434 "Not Defined" 64433 "Not Defined" 64432 "Not Defined" 64431 "Not Defined" 64430 "Not Defined" 64429 "Not Defined" 64428 "Not Defined" 64427 "Not Defined" 64426 "Not Defined" 64425 "Not Defined" 64424 "Not Defined" 64423 "Not Defined" 64422 "Not Defined" 64421 "Not Defined" 64420 "Not Defined" 64419 "Not Defined" 64418 "Not Defined" 64417 "Not Defined" 64416 "Not Defined" 64415 "Not Defined" 64414 "Not Defined" 64413 "Not Defined" 64412 "Not Defined" 64411 "Not Defined" 64410 "Not Defined" 64409 "Not Defined" 64408 "Not Defined" 64407 "Not Defined" 64406 "Not Defined" 64405 "Not Defined" 64404 "Not Defined" 64403 "Not Defined" 64402 "Not Defined" 64401 "Not Defined" 64400 "Not Defined" 64399 "Not Defined" 64398 "Not Defined" 64397 "Not Defined" 64396 "Not Defined" 64395 "Not Defined" 64394 "Not Defined" 64393 "Not Defined" 64392 "Not Defined" 64391 "Not Defined" 64390 "Not Defined" 64389 "Not Defined" 64388 "Not Defined" 64387 "Not Defined" 64386 "Not Defined" 64385 "Not Defined" 64384 "Not Defined" 64383 "Not Defined" 64382 "Not Defined" 64381 "Not Defined" 64380 "Not Defined" 64379 "Not Defined" 64378 "Not Defined" 64377 "Not Defined" 64376 "Not Defined" 64375 "Not Defined" 64374 "Not Defined" 64373 "Not Defined" 64372 "Not Defined" 64371 "Not Defined" 64370 "Not Defined" 64369 "Not Defined" 64368 "Not Defined" 64367 "Not Defined" 64366 "Not Defined" 64365 "Not Defined" 64364 "Not Defined" 64363 "Not Defined" 64362 "Not Defined" 64361 "Not Defined" 64360 "Not Defined" 64359 "Not Defined" 64358 "Not Defined" 64357 "Not Defined" 64356 "Not Defined" 64355 "Not Defined" 64354 "Not Defined" 64353 "Not Defined" 64352 "Not Defined" 64351 "Not Defined" 64350 "Not Defined" 64349 "Not Defined" 64348 "Not Defined" 64347 "Not Defined" 64346 "Not Defined" 64345 "Not Defined" 64344 "Not Defined" 64343 "Not Defined" 64342 "Not Defined" 64341 "Not Defined" 64340 "Not Defined" 64339 "Not Defined" 64338 "Not Defined" 64337 "Not Defined" 64336 "Not Defined" 64335 "Not Defined" 64334 "Not Defined" 64333 "Not Defined" 64332 "Not Defined" 64331 "Not Defined" 64330 "Not Defined" 64329 "Not Defined" 64328 "Not Defined" 64327 "Not Defined" 64326 "Not Defined" 64325 "Not Defined" 64324 "Not Defined" 64323 "Not Defined" 64322 "Not Defined" 64321 "Not Defined" 64320 "Not Defined" 64319 "Not Defined" 64318 "Not Defined" 64317 "Not Defined" 64316 "Not Defined" 64315 "Not Defined" 64314 "Not Defined" 64313 "Not Defined" 64312 "Not Defined" 64311 "Not Defined" 64310 "Not Defined" 64309 "Not Defined" 64308 "Not Defined" 64307 "Not Defined" 64306 "Not Defined" 64305 "Not Defined" 64304 "Not Defined" 64303 "Not Defined" 64302 "Not Defined" 64301 "Not Defined" 64300 "Not Defined" 64299 "Not Defined" 64298 "Not Defined" 64297 "Not Defined" 64296 "Not Defined" 64295 "Not Defined" 64294 "Not Defined" 64293 "Not Defined" 64292 "Not Defined" 64291 "Not Defined" 64290 "Not Defined" 64289 "Not Defined" 64288 "Not Defined" 64287 "Not Defined" 64286 "Not Defined" 64285 "Not Defined" 64284 "Not Defined" 64283 "Not Defined" 64282 "Not Defined" 64281 "Not Defined" 64280 "Not Defined" 64279 "Not Defined" 64278 "Not Defined" 64277 "Not Defined" 64276 "Not Defined" 64275 "Not Defined" 64274 "Not Defined" 64273 "Not Defined" 64272 "Not Defined" 64271 "Not Defined" 64270 "Not Defined" 64269 "Not Defined" 64268 "Not Defined" 64267 "Not Defined" 64266 "Not Defined" 64265 "Not Defined" 64264 "Not Defined" 64263 "Not Defined" 64262 "Not Defined" 64261 "Not Defined" 64260 "Not Defined" 64259 "Not Defined" 64258 "Not Defined" 64257 "Not Defined" 64256 "Not Defined" ;
VAL_ 2680225666 ETSS_SupplyVoltageSimpleState 12 "Normal" 11 "Failure" 10 "Crab" 9 "Manual" 8 "Centring" 7 "Unknown" 6 "Diagnostic" 5 "Failure" 4 "Waiting for Movement" 3 "Initialise" 2 "Checking..." 1 "Failure" 0 "Ok" ;
VAL_ 2680225666 ETSS_SpeedSignalSimpleStatus 12 "Normal" 11 "Failure" 10 "Crab" 9 "Manual" 8 "Centring" 7 "Unknown" 6 "Diagnostic" 5 "Failure" 4 "Waiting for Movement" 3 "Initialise" 2 "Checking..." 1 "Failure" 0 "Ok" ;
VAL_ 2680225666 ETSS_EtsSimpleStatus 12 "Normal" 11 "Failure" 10 "Crab" 9 "Manual" 8 "Centring" 7 "Unknown" 6 "Diagnostic" 5 "Failure" 4 "Waiting for Movement" 3 "Initialise" 2 "Checking..." 1 "Failure" 0 "Ok" ;
VAL_ 2680225666 ETSS_SteerMode 15 "Not Defined" 14 "Not Defined" 13 "Not Defined" 12 "Not Defined" 11 "Not Defined" 10 "Not Defined" 9 "Not Defined" 8 "Not Defined" 7 "Not Defined" 6 "Not Defined" 5 "Not Defined" 4 "Not Defined" 3 "Not Defined" 2 "Crab " 1 "Normal" 0 "Manual" ;
VAL_ 2680225666 ETSS_DiagnosticState 1 "Diagnostic Session Active" 0 "No Diagnostic Session Active" ;
VAL_ 2680225666 ETSS_AlarmState 1 "Alarm(s) Active" 0 "No alarm active" ;
VAL_ 2680225666 ETSS_SteeringState 1 "ETS Operational" 0 "ETS Initialise" ;
